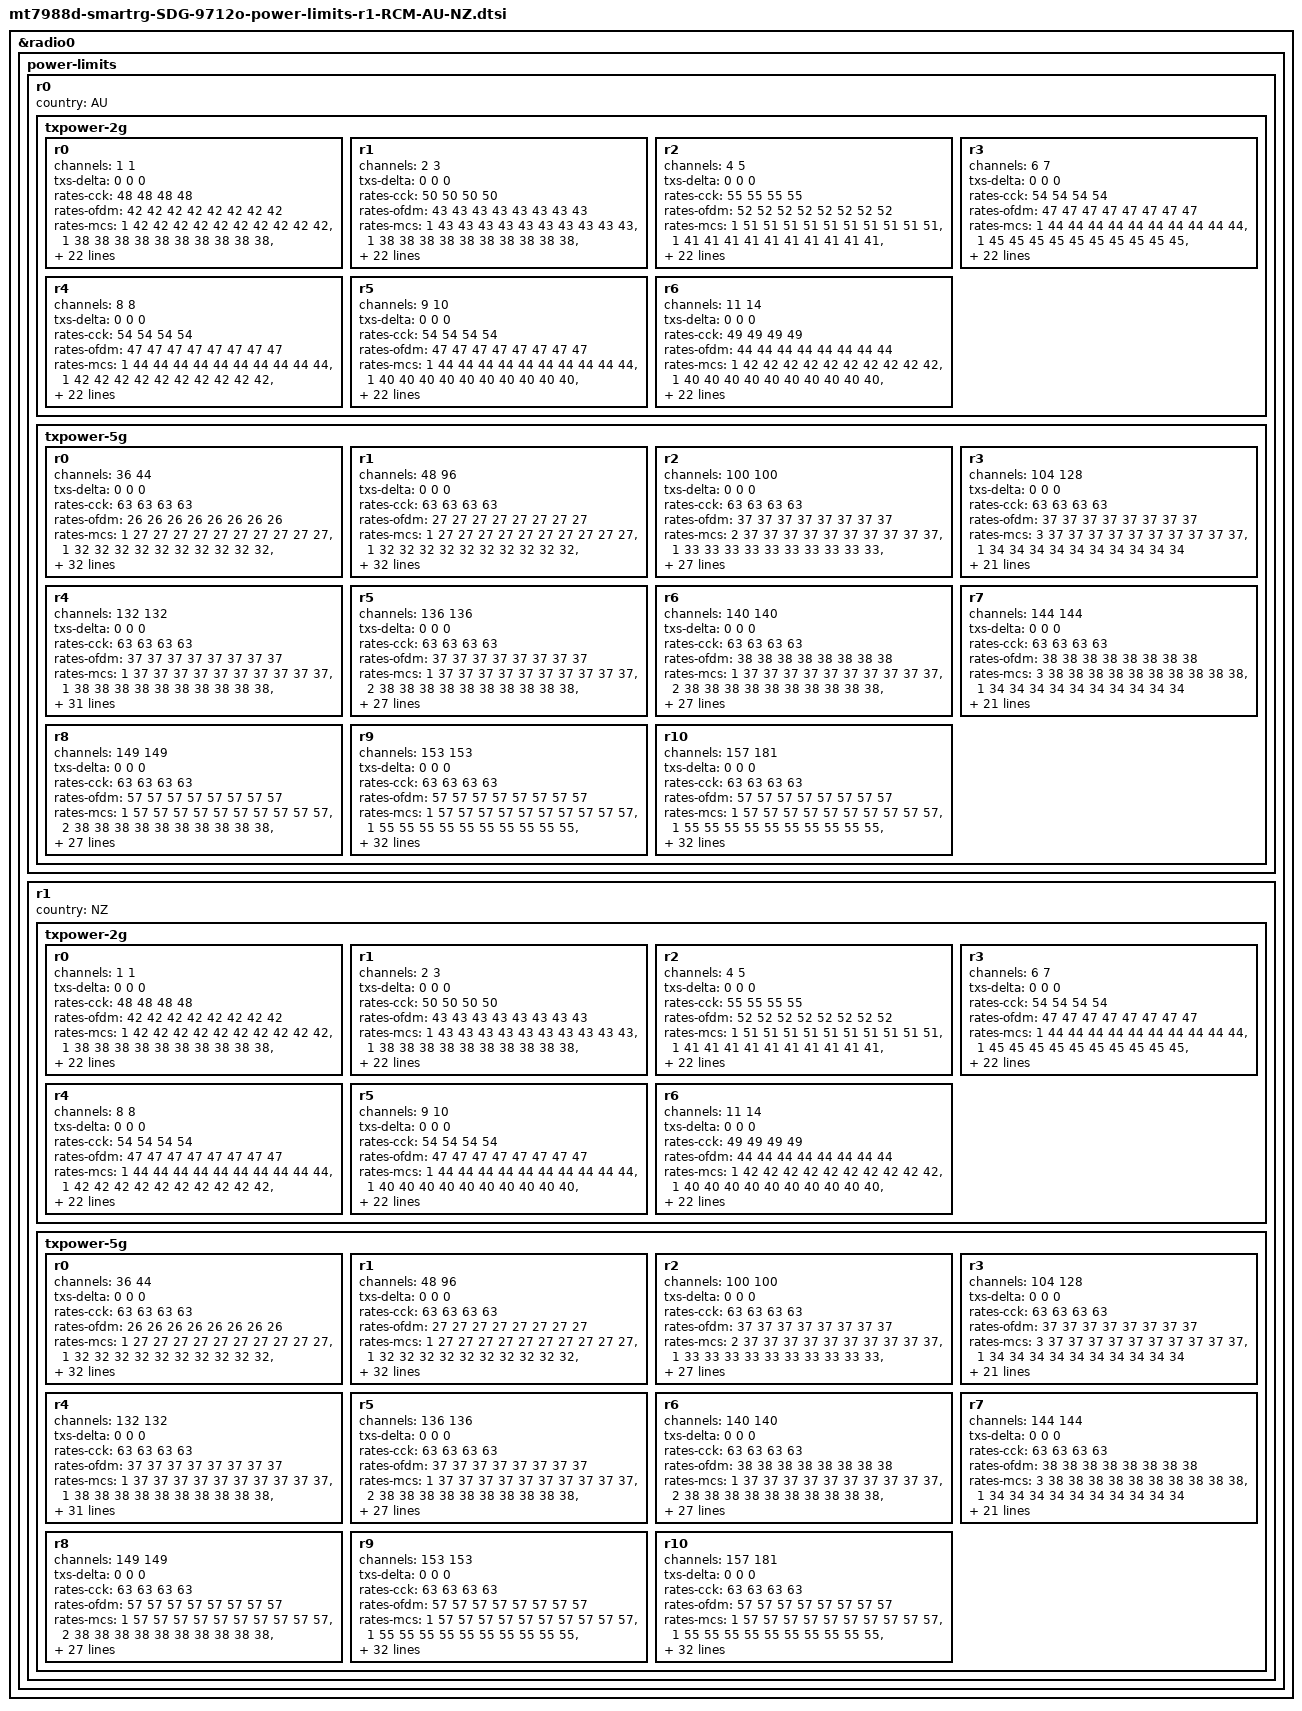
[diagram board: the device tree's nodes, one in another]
// SPDX-License-Identifier: (GPL-2.0 OR MIT)
/*
 * Copyright (C) 2024 SmartRG Inc.
 * Author: Chad Monroe <chad.monroe@smartrg.com>
 */

&radio0 {
	power-limits {
		r0 {
			country = "AU";

			txpower-2g {
				r0 {
					channels = <1 1>;
					txs-delta = <0 0 0>;
					rates-cck = /bits/ 8 <48 48 48 48>;
					rates-ofdm = /bits/ 8 <42 42 42 42 42 42 42 42>;
					rates-mcs =
					/bits/ 8 <1 42 42 42 42 42 42 42 42 42 42>,
					/bits/ 8 <1 38 38 38 38 38 38 38 38 38 38>,
					/bits/ 8 <2 63 63 63 63 63 63 63 63 63 63>;
					rates-ru =
					/bits/ 8 <4 42 42 42 42 42 42 42 42 42 42 42 42>,
					/bits/ 8 <1 38 38 38 38 38 38 38 38 38 38 38 38>,
					/bits/ 8 <2 63 63 63 63 63 63 63 63 63 63 63 63>;
					rates-eht =
					/bits/ 8 <4 42 42 42 42 42 42 42 42 42 42 42 42 42 42 42 42>,
					/bits/ 8 <1 38 38 38 38 38 38 38 38 38 38 38 38 38 38 38 38>,
					/bits/ 8 <3 63 63 63 63 63 63 63 63 63 63 63 63 63 63 63 63>,
					/bits/ 8 <2 42 42 42 42 42 42 42 42 42 42 42 42 42 42 42 42>,
					/bits/ 8 <6 63 63 63 63 63 63 63 63 63 63 63 63 63 63 63 63>;
					paths-cck = /bits/ 8 <48 42 38 36 34>;
					paths-ofdm = /bits/ 8 <42 36 32 30 28>;
					paths-ofdm-bf = /bits/ 8 <30 23 18 14>;
					paths-ru =
					/bits/ 8 <6 42 36 32 30 28 36 32 30 28 32 30 28 30 28 28>,
					/bits/ 8 <1 38 32 28 26 24 32 28 26 24 28 26 24 26 24 24>,
					/bits/ 8 <9 63 63 63 63 63 63 63 63 63 63 63 63 63 63 63>;
					paths-ru-bf =
					/bits/ 8 <6 42 30 23 18 14 36 29 24 20 32 27 24 30 26 28>,
					/bits/ 8 <1 38 26 19 14 10 32 25 20 16 28 23 20 26 22 24>,
					/bits/ 8 <9 63 63 63 63 63 63 63 63 63 63 63 63 63 63 63>;
				};
				r1 {
					channels = <2 3>;
					txs-delta = <0 0 0>;
					rates-cck = /bits/ 8 <50 50 50 50>;
					rates-ofdm = /bits/ 8 <43 43 43 43 43 43 43 43>;
					rates-mcs =
					/bits/ 8 <1 43 43 43 43 43 43 43 43 43 43>,
					/bits/ 8 <1 38 38 38 38 38 38 38 38 38 38>,
					/bits/ 8 <2 63 63 63 63 63 63 63 63 63 63>;
					rates-ru =
					/bits/ 8 <4 43 43 43 43 43 43 43 43 43 43 43 43>,
					/bits/ 8 <1 38 38 38 38 38 38 38 38 38 38 38 38>,
					/bits/ 8 <2 63 63 63 63 63 63 63 63 63 63 63 63>;
					rates-eht =
					/bits/ 8 <4 43 43 43 43 43 43 43 43 43 43 43 43 43 43 43 43>,
					/bits/ 8 <1 38 38 38 38 38 38 38 38 38 38 38 38 38 38 38 38>,
					/bits/ 8 <3 63 63 63 63 63 63 63 63 63 63 63 63 63 63 63 63>,
					/bits/ 8 <2 43 43 43 43 43 43 43 43 43 43 43 43 43 43 43 43>,
					/bits/ 8 <6 63 63 63 63 63 63 63 63 63 63 63 63 63 63 63 63>;
					paths-cck = /bits/ 8 <50 44 40 38 36>;
					paths-ofdm = /bits/ 8 <43 37 33 31 29>;
					paths-ofdm-bf = /bits/ 8 <31 24 19 15>;
					paths-ru =
					/bits/ 8 <6 43 37 33 31 29 37 33 31 29 33 31 29 31 29 29>,
					/bits/ 8 <1 38 32 28 26 24 32 28 26 24 28 26 24 26 24 24>,
					/bits/ 8 <9 63 63 63 63 63 63 63 63 63 63 63 63 63 63 63>;
					paths-ru-bf =
					/bits/ 8 <6 43 31 24 19 15 37 30 25 21 33 28 25 31 27 29>,
					/bits/ 8 <1 38 26 19 14 10 32 25 20 16 28 23 20 26 22 24>,
					/bits/ 8 <9 63 63 63 63 63 63 63 63 63 63 63 63 63 63 63>;
				};
				r2 {
					channels = <4 5>;
					txs-delta = <0 0 0>;
					rates-cck = /bits/ 8 <55 55 55 55>;
					rates-ofdm = /bits/ 8 <52 52 52 52 52 52 52 52>;
					rates-mcs =
					/bits/ 8 <1 51 51 51 51 51 51 51 51 51 51>,
					/bits/ 8 <1 41 41 41 41 41 41 41 41 41 41>,
					/bits/ 8 <2 63 63 63 63 63 63 63 63 63 63>;
					rates-ru =
					/bits/ 8 <4 51 51 51 51 51 51 51 51 51 51 51 51>,
					/bits/ 8 <1 41 41 41 41 41 41 41 41 41 41 41 41>,
					/bits/ 8 <2 63 63 63 63 63 63 63 63 63 63 63 63>;
					rates-eht =
					/bits/ 8 <4 51 51 51 51 51 51 51 51 51 51 51 51 51 51 51 51>,
					/bits/ 8 <1 41 41 41 41 41 41 41 41 41 41 41 41 41 41 41 41>,
					/bits/ 8 <3 63 63 63 63 63 63 63 63 63 63 63 63 63 63 63 63>,
					/bits/ 8 <2 51 51 51 51 51 51 51 51 51 51 51 51 51 51 51 51>,
					/bits/ 8 <6 63 63 63 63 63 63 63 63 63 63 63 63 63 63 63 63>;
					paths-cck = /bits/ 8 <55 49 45 43 41>;
					paths-ofdm = /bits/ 8 <52 46 42 40 38>;
					paths-ofdm-bf = /bits/ 8 <40 33 28 24>;
					paths-ru =
					/bits/ 8 <6 51 45 41 39 37 45 41 39 37 41 39 37 39 37 37>,
					/bits/ 8 <1 41 35 31 29 27 35 31 29 27 31 29 27 29 27 27>,
					/bits/ 8 <9 63 63 63 63 63 63 63 63 63 63 63 63 63 63 63>;
					paths-ru-bf =
					/bits/ 8 <6 51 39 32 27 23 45 38 33 29 41 36 33 39 35 37>,
					/bits/ 8 <1 41 29 22 17 13 35 28 23 19 31 26 23 29 25 27>,
					/bits/ 8 <9 63 63 63 63 63 63 63 63 63 63 63 63 63 63 63>;
				};
				r3 {
					channels = <6 7>;
					txs-delta = <0 0 0>;
					rates-cck = /bits/ 8 <54 54 54 54>;
					rates-ofdm = /bits/ 8 <47 47 47 47 47 47 47 47>;
					rates-mcs =
					/bits/ 8 <1 44 44 44 44 44 44 44 44 44 44>,
					/bits/ 8 <1 45 45 45 45 45 45 45 45 45 45>,
					/bits/ 8 <2 63 63 63 63 63 63 63 63 63 63>;
					rates-ru =
					/bits/ 8 <4 44 44 44 44 44 44 44 44 44 44 44 44>,
					/bits/ 8 <1 45 45 45 45 45 45 45 45 45 45 45 45>,
					/bits/ 8 <2 63 63 63 63 63 63 63 63 63 63 63 63>;
					rates-eht =
					/bits/ 8 <4 44 44 44 44 44 44 44 44 44 44 44 44 44 44 44 44>,
					/bits/ 8 <1 45 45 45 45 45 45 45 45 45 45 45 45 45 45 45 45>,
					/bits/ 8 <3 63 63 63 63 63 63 63 63 63 63 63 63 63 63 63 63>,
					/bits/ 8 <2 44 44 44 44 44 44 44 44 44 44 44 44 44 44 44 44>,
					/bits/ 8 <6 63 63 63 63 63 63 63 63 63 63 63 63 63 63 63 63>;
					paths-cck = /bits/ 8 <54 48 44 42 40>;
					paths-ofdm = /bits/ 8 <47 41 37 35 33>;
					paths-ofdm-bf = /bits/ 8 <35 28 23 19>;
					paths-ru =
					/bits/ 8 <6 44 38 34 32 30 38 34 32 30 34 32 30 32 30 30>,
					/bits/ 8 <1 45 39 35 33 31 39 35 33 31 35 33 31 33 31 31>,
					/bits/ 8 <9 63 63 63 63 63 63 63 63 63 63 63 63 63 63 63>;
					paths-ru-bf =
					/bits/ 8 <6 44 32 25 20 16 38 31 26 22 34 29 26 32 28 30>,
					/bits/ 8 <1 45 33 26 21 17 39 32 27 23 35 30 27 33 29 31>,
					/bits/ 8 <9 63 63 63 63 63 63 63 63 63 63 63 63 63 63 63>;
				};
				r4 {
					channels = <8 8>;
					txs-delta = <0 0 0>;
					rates-cck = /bits/ 8 <54 54 54 54>;
					rates-ofdm = /bits/ 8 <47 47 47 47 47 47 47 47>;
					rates-mcs =
					/bits/ 8 <1 44 44 44 44 44 44 44 44 44 44>,
					/bits/ 8 <1 42 42 42 42 42 42 42 42 42 42>,
					/bits/ 8 <2 63 63 63 63 63 63 63 63 63 63>;
					rates-ru =
					/bits/ 8 <4 44 44 44 44 44 44 44 44 44 44 44 44>,
					/bits/ 8 <1 42 42 42 42 42 42 42 42 42 42 42 42>,
					/bits/ 8 <2 63 63 63 63 63 63 63 63 63 63 63 63>;
					rates-eht =
					/bits/ 8 <4 44 44 44 44 44 44 44 44 44 44 44 44 44 44 44 44>,
					/bits/ 8 <1 42 42 42 42 42 42 42 42 42 42 42 42 42 42 42 42>,
					/bits/ 8 <3 63 63 63 63 63 63 63 63 63 63 63 63 63 63 63 63>,
					/bits/ 8 <2 44 44 44 44 44 44 44 44 44 44 44 44 44 44 44 44>,
					/bits/ 8 <6 63 63 63 63 63 63 63 63 63 63 63 63 63 63 63 63>;
					paths-cck = /bits/ 8 <54 48 44 42 40>;
					paths-ofdm = /bits/ 8 <47 41 37 35 33>;
					paths-ofdm-bf = /bits/ 8 <35 28 23 19>;
					paths-ru =
					/bits/ 8 <6 44 38 34 32 30 38 34 32 30 34 32 30 32 30 30>,
					/bits/ 8 <1 42 36 32 30 28 36 32 30 28 32 30 28 30 28 28>,
					/bits/ 8 <9 63 63 63 63 63 63 63 63 63 63 63 63 63 63 63>;
					paths-ru-bf =
					/bits/ 8 <6 44 32 25 20 16 38 31 26 22 34 29 26 32 28 30>,
					/bits/ 8 <1 42 30 23 18 14 36 29 24 20 32 27 24 30 26 28>,
					/bits/ 8 <9 63 63 63 63 63 63 63 63 63 63 63 63 63 63 63>;
				};
				r5 {
					channels = <9 10>;
					txs-delta = <0 0 0>;
					rates-cck = /bits/ 8 <54 54 54 54>;
					rates-ofdm = /bits/ 8 <47 47 47 47 47 47 47 47>;
					rates-mcs =
					/bits/ 8 <1 44 44 44 44 44 44 44 44 44 44>,
					/bits/ 8 <1 40 40 40 40 40 40 40 40 40 40>,
					/bits/ 8 <2 63 63 63 63 63 63 63 63 63 63>;
					rates-ru =
					/bits/ 8 <4 44 44 44 44 44 44 44 44 44 44 44 44>,
					/bits/ 8 <1 40 40 40 40 40 40 40 40 40 40 40 40>,
					/bits/ 8 <2 63 63 63 63 63 63 63 63 63 63 63 63>;
					rates-eht =
					/bits/ 8 <4 44 44 44 44 44 44 44 44 44 44 44 44 44 44 44 44>,
					/bits/ 8 <1 40 40 40 40 40 40 40 40 40 40 40 40 40 40 40 40>,
					/bits/ 8 <3 63 63 63 63 63 63 63 63 63 63 63 63 63 63 63 63>,
					/bits/ 8 <2 44 44 44 44 44 44 44 44 44 44 44 44 44 44 44 44>,
					/bits/ 8 <6 63 63 63 63 63 63 63 63 63 63 63 63 63 63 63 63>;
					paths-cck = /bits/ 8 <54 48 44 42 40>;
					paths-ofdm = /bits/ 8 <47 41 37 35 33>;
					paths-ofdm-bf = /bits/ 8 <35 28 23 19>;
					paths-ru =
					/bits/ 8 <6 44 38 34 32 30 38 34 32 30 34 32 30 32 30 30>,
					/bits/ 8 <1 40 34 30 28 26 34 30 28 26 30 28 26 28 26 26>,
					/bits/ 8 <9 63 63 63 63 63 63 63 63 63 63 63 63 63 63 63>;
					paths-ru-bf =
					/bits/ 8 <6 44 32 25 20 16 38 31 26 22 34 29 26 32 28 30>,
					/bits/ 8 <1 40 28 21 16 12 34 27 22 18 30 25 22 28 24 26>,
					/bits/ 8 <9 63 63 63 63 63 63 63 63 63 63 63 63 63 63 63>;
				};
				r6 {
					channels = <11 14>;
					txs-delta = <0 0 0>;
					rates-cck = /bits/ 8 <49 49 49 49>;
					rates-ofdm = /bits/ 8 <44 44 44 44 44 44 44 44>;
					rates-mcs =
					/bits/ 8 <1 42 42 42 42 42 42 42 42 42 42>,
					/bits/ 8 <1 40 40 40 40 40 40 40 40 40 40>,
					/bits/ 8 <2 63 63 63 63 63 63 63 63 63 63>;
					rates-ru =
					/bits/ 8 <4 42 42 42 42 42 42 42 42 42 42 42 42>,
					/bits/ 8 <1 40 40 40 40 40 40 40 40 40 40 40 40>,
					/bits/ 8 <2 63 63 63 63 63 63 63 63 63 63 63 63>;
					rates-eht =
					/bits/ 8 <4 42 42 42 42 42 42 42 42 42 42 42 42 42 42 42 42>,
					/bits/ 8 <1 40 40 40 40 40 40 40 40 40 40 40 40 40 40 40 40>,
					/bits/ 8 <3 63 63 63 63 63 63 63 63 63 63 63 63 63 63 63 63>,
					/bits/ 8 <2 42 42 42 42 42 42 42 42 42 42 42 42 42 42 42 42>,
					/bits/ 8 <6 63 63 63 63 63 63 63 63 63 63 63 63 63 63 63 63>;
					paths-cck = /bits/ 8 <49 43 39 37 35>;
					paths-ofdm = /bits/ 8 <44 38 34 32 30>;
					paths-ofdm-bf = /bits/ 8 <32 25 20 16>;
					paths-ru =
					/bits/ 8 <6 42 36 32 30 28 36 32 30 28 32 30 28 30 28 28>,
					/bits/ 8 <1 40 34 30 28 26 34 30 28 26 30 28 26 28 26 26>,
					/bits/ 8 <9 63 63 63 63 63 63 63 63 63 63 63 63 63 63 63>;
					paths-ru-bf =
					/bits/ 8 <6 42 30 23 18 14 36 29 24 20 32 27 24 30 26 28>,
					/bits/ 8 <1 40 28 21 16 12 34 27 22 18 30 25 22 28 24 26>,
					/bits/ 8 <9 63 63 63 63 63 63 63 63 63 63 63 63 63 63 63>;
				};
			};
			txpower-5g {
				r0 {
					channels = <36 44>;
					txs-delta = <0 0 0>;
					rates-cck = /bits/ 8 <63 63 63 63>;
					rates-ofdm = /bits/ 8 <26 26 26 26 26 26 26 26>;
					rates-mcs =
					/bits/ 8 <1 27 27 27 27 27 27 27 27 27 27>,
					/bits/ 8 <1 32 32 32 32 32 32 32 32 32 32>,
					/bits/ 8 <1 33 33 33 33 33 33 33 33 33 33>,
					/bits/ 8 <1 34 34 34 34 34 34 34 34 34 34>;
					rates-ru =
					/bits/ 8 <4 27 27 27 27 27 27 27 27 27 27 27 27>,
					/bits/ 8 <1 32 32 32 32 32 32 32 32 32 32 32 32>,
					/bits/ 8 <1 33 33 33 33 33 33 33 33 33 33 33 33>,
					/bits/ 8 <1 34 34 34 34 34 34 34 34 34 34 34 34>;
					rates-eht =
					/bits/ 8 <4 27 27 27 27 27 27 27 27 27 27 27 27 27 27 27 27>,
					/bits/ 8 <1 32 32 32 32 32 32 32 32 32 32 32 32 32 32 32 32>,
					/bits/ 8 <1 33 33 33 33 33 33 33 33 33 33 33 33 33 33 33 33>,
					/bits/ 8 <1 34 34 34 34 34 34 34 34 34 34 34 34 34 34 34 34>,
					/bits/ 8 <1 63 63 63 63 63 63 63 63 63 63 63 63 63 63 63 63>,
					/bits/ 8 <2 27 27 27 27 27 27 27 27 27 27 27 27 27 27 27 27>,
					/bits/ 8 <1 33 33 33 33 33 33 33 33 33 33 33 33 33 33 33 33>,
					/bits/ 8 <2 34 34 34 34 34 34 34 34 34 34 34 34 34 34 34 34>,
					/bits/ 8 <3 63 63 63 63 63 63 63 63 63 63 63 63 63 63 63 63>;
					paths-cck = /bits/ 8 <63 63 63 63 63>;
					paths-ofdm = /bits/ 8 <26 20 16 14 12>;
					paths-ofdm-bf = /bits/ 8 <14 7 2 0>;
					paths-ru =
					/bits/ 8 <6 27 21 17 15 13 21 17 15 13 17 15 13 15 13 13>,
					/bits/ 8 <1 32 26 22 20 18 26 22 20 18 22 20 18 20 18 18>,
					/bits/ 8 <2 33 27 23 21 19 27 23 21 19 23 21 19 21 19 19>,
					/bits/ 8 <3 34 28 24 22 20 28 24 22 20 24 22 20 22 20 20>,
					/bits/ 8 <4 63 63 63 63 63 63 63 63 63 63 63 63 63 63 63>;
					paths-ru-bf =
					/bits/ 8 <6 27 15 8 3 0 21 14 9 5 17 12 9 15 11 13>,
					/bits/ 8 <1 32 20 13 8 4 26 19 14 10 22 17 14 20 16 18>,
					/bits/ 8 <2 33 21 14 9 5 27 20 15 11 23 18 15 21 17 19>,
					/bits/ 8 <3 34 22 15 10 6 28 21 16 12 24 19 16 22 18 20>,
					/bits/ 8 <4 63 63 63 63 63 63 63 63 63 63 63 63 63 63 63>;
				};
				r1 {
					channels = <48 96>;
					txs-delta = <0 0 0>;
					rates-cck = /bits/ 8 <63 63 63 63>;
					rates-ofdm = /bits/ 8 <27 27 27 27 27 27 27 27>;
					rates-mcs =
					/bits/ 8 <1 27 27 27 27 27 27 27 27 27 27>,
					/bits/ 8 <1 32 32 32 32 32 32 32 32 32 32>,
					/bits/ 8 <1 33 33 33 33 33 33 33 33 33 33>,
					/bits/ 8 <1 34 34 34 34 34 34 34 34 34 34>;
					rates-ru =
					/bits/ 8 <4 27 27 27 27 27 27 27 27 27 27 27 27>,
					/bits/ 8 <1 32 32 32 32 32 32 32 32 32 32 32 32>,
					/bits/ 8 <1 33 33 33 33 33 33 33 33 33 33 33 33>,
					/bits/ 8 <1 34 34 34 34 34 34 34 34 34 34 34 34>;
					rates-eht =
					/bits/ 8 <4 27 27 27 27 27 27 27 27 27 27 27 27 27 27 27 27>,
					/bits/ 8 <1 32 32 32 32 32 32 32 32 32 32 32 32 32 32 32 32>,
					/bits/ 8 <1 33 33 33 33 33 33 33 33 33 33 33 33 33 33 33 33>,
					/bits/ 8 <1 34 34 34 34 34 34 34 34 34 34 34 34 34 34 34 34>,
					/bits/ 8 <1 63 63 63 63 63 63 63 63 63 63 63 63 63 63 63 63>,
					/bits/ 8 <2 27 27 27 27 27 27 27 27 27 27 27 27 27 27 27 27>,
					/bits/ 8 <1 33 33 33 33 33 33 33 33 33 33 33 33 33 33 33 33>,
					/bits/ 8 <2 34 34 34 34 34 34 34 34 34 34 34 34 34 34 34 34>,
					/bits/ 8 <3 63 63 63 63 63 63 63 63 63 63 63 63 63 63 63 63>;
					paths-cck = /bits/ 8 <63 63 63 63 63>;
					paths-ofdm = /bits/ 8 <27 21 17 15 13>;
					paths-ofdm-bf = /bits/ 8 <15 8 3 0>;
					paths-ru =
					/bits/ 8 <6 27 21 17 15 13 21 17 15 13 17 15 13 15 13 13>,
					/bits/ 8 <1 32 26 22 20 18 26 22 20 18 22 20 18 20 18 18>,
					/bits/ 8 <2 33 27 23 21 19 27 23 21 19 23 21 19 21 19 19>,
					/bits/ 8 <3 34 28 24 22 20 28 24 22 20 24 22 20 22 20 20>,
					/bits/ 8 <4 63 63 63 63 63 63 63 63 63 63 63 63 63 63 63>;
					paths-ru-bf =
					/bits/ 8 <6 27 15 8 3 0 21 14 9 5 17 12 9 15 11 13>,
					/bits/ 8 <1 32 20 13 8 4 26 19 14 10 22 17 14 20 16 18>,
					/bits/ 8 <2 33 21 14 9 5 27 20 15 11 23 18 15 21 17 19>,
					/bits/ 8 <3 34 22 15 10 6 28 21 16 12 24 19 16 22 18 20>,
					/bits/ 8 <4 63 63 63 63 63 63 63 63 63 63 63 63 63 63 63>;
				};
				r2 {
					channels = <100 100>;
					txs-delta = <0 0 0>;
					rates-cck = /bits/ 8 <63 63 63 63>;
					rates-ofdm = /bits/ 8 <37 37 37 37 37 37 37 37>;
					rates-mcs =
					/bits/ 8 <2 37 37 37 37 37 37 37 37 37 37>,
					/bits/ 8 <1 33 33 33 33 33 33 33 33 33 33>,
					/bits/ 8 <1 34 34 34 34 34 34 34 34 34 34>;
					rates-ru =
					/bits/ 8 <5 37 37 37 37 37 37 37 37 37 37 37 37>,
					/bits/ 8 <1 33 33 33 33 33 33 33 33 33 33 33 33>,
					/bits/ 8 <1 34 34 34 34 34 34 34 34 34 34 34 34>;
					rates-eht =
					/bits/ 8 <5 37 37 37 37 37 37 37 37 37 37 37 37 37 37 37 37>,
					/bits/ 8 <1 33 33 33 33 33 33 33 33 33 33 33 33 33 33 33 33>,
					/bits/ 8 <1 34 34 34 34 34 34 34 34 34 34 34 34 34 34 34 34>,
					/bits/ 8 <1 63 63 63 63 63 63 63 63 63 63 63 63 63 63 63 63>,
					/bits/ 8 <2 37 37 37 37 37 37 37 37 37 37 37 37 37 37 37 37>,
					/bits/ 8 <1 33 33 33 33 33 33 33 33 33 33 33 33 33 33 33 33>,
					/bits/ 8 <2 34 34 34 34 34 34 34 34 34 34 34 34 34 34 34 34>,
					/bits/ 8 <3 63 63 63 63 63 63 63 63 63 63 63 63 63 63 63 63>;
					paths-cck = /bits/ 8 <63 63 63 63 63>;
					paths-ofdm = /bits/ 8 <37 31 27 25 23>;
					paths-ofdm-bf = /bits/ 8 <25 18 13 9>;
					paths-ru =
					/bits/ 8 <7 37 31 27 25 23 31 27 25 23 27 25 23 25 23 23>,
					/bits/ 8 <2 33 27 23 21 19 27 23 21 19 23 21 19 21 19 19>,
					/bits/ 8 <3 34 28 24 22 20 28 24 22 20 24 22 20 22 20 20>,
					/bits/ 8 <4 63 63 63 63 63 63 63 63 63 63 63 63 63 63 63>;
					paths-ru-bf =
					/bits/ 8 <7 37 25 18 13 9 31 24 19 15 27 22 19 25 21 23>,
					/bits/ 8 <2 33 21 14 9 5 27 20 15 11 23 18 15 21 17 19>,
					/bits/ 8 <3 34 22 15 10 6 28 21 16 12 24 19 16 22 18 20>,
					/bits/ 8 <4 63 63 63 63 63 63 63 63 63 63 63 63 63 63 63>;
				};
				r3 {
					channels = <104 128>;
					txs-delta = <0 0 0>;
					rates-cck = /bits/ 8 <63 63 63 63>;
					rates-ofdm = /bits/ 8 <37 37 37 37 37 37 37 37>;
					rates-mcs =
					/bits/ 8 <3 37 37 37 37 37 37 37 37 37 37>,
					/bits/ 8 <1 34 34 34 34 34 34 34 34 34 34>;
					rates-ru =
					/bits/ 8 <6 37 37 37 37 37 37 37 37 37 37 37 37>,
					/bits/ 8 <1 34 34 34 34 34 34 34 34 34 34 34 34>;
					rates-eht =
					/bits/ 8 <6 37 37 37 37 37 37 37 37 37 37 37 37 37 37 37 37>,
					/bits/ 8 <1 34 34 34 34 34 34 34 34 34 34 34 34 34 34 34 34>,
					/bits/ 8 <1 63 63 63 63 63 63 63 63 63 63 63 63 63 63 63 63>,
					/bits/ 8 <3 37 37 37 37 37 37 37 37 37 37 37 37 37 37 37 37>,
					/bits/ 8 <2 34 34 34 34 34 34 34 34 34 34 34 34 34 34 34 34>,
					/bits/ 8 <3 63 63 63 63 63 63 63 63 63 63 63 63 63 63 63 63>;
					paths-cck = /bits/ 8 <63 63 63 63 63>;
					paths-ofdm = /bits/ 8 <37 31 27 25 23>;
					paths-ofdm-bf = /bits/ 8 <25 18 13 9>;
					paths-ru =
					/bits/ 8 <9 37 31 27 25 23 31 27 25 23 27 25 23 25 23 23>,
					/bits/ 8 <3 34 28 24 22 20 28 24 22 20 24 22 20 22 20 20>,
					/bits/ 8 <4 63 63 63 63 63 63 63 63 63 63 63 63 63 63 63>;
					paths-ru-bf =
					/bits/ 8 <9 37 25 18 13 9 31 24 19 15 27 22 19 25 21 23>,
					/bits/ 8 <3 34 22 15 10 6 28 21 16 12 24 19 16 22 18 20>,
					/bits/ 8 <4 63 63 63 63 63 63 63 63 63 63 63 63 63 63 63>;
				};
				r4 {
					channels = <132 132>;
					txs-delta = <0 0 0>;
					rates-cck = /bits/ 8 <63 63 63 63>;
					rates-ofdm = /bits/ 8 <37 37 37 37 37 37 37 37>;
					rates-mcs =
					/bits/ 8 <1 37 37 37 37 37 37 37 37 37 37>,
					/bits/ 8 <1 38 38 38 38 38 38 38 38 38 38>,
					/bits/ 8 <1 37 37 37 37 37 37 37 37 37 37>,
					/bits/ 8 <1 34 34 34 34 34 34 34 34 34 34>;
					rates-ru =
					/bits/ 8 <4 37 37 37 37 37 37 37 37 37 37 37 37>,
					/bits/ 8 <1 38 38 38 38 38 38 38 38 38 38 38 38>,
					/bits/ 8 <1 37 37 37 37 37 37 37 37 37 37 37 37>,
					/bits/ 8 <1 34 34 34 34 34 34 34 34 34 34 34 34>;
					rates-eht =
					/bits/ 8 <4 37 37 37 37 37 37 37 37 37 37 37 37 37 37 37 37>,
					/bits/ 8 <1 38 38 38 38 38 38 38 38 38 38 38 38 38 38 38 38>,
					/bits/ 8 <1 37 37 37 37 37 37 37 37 37 37 37 37 37 37 37 37>,
					/bits/ 8 <1 34 34 34 34 34 34 34 34 34 34 34 34 34 34 34 34>,
					/bits/ 8 <1 63 63 63 63 63 63 63 63 63 63 63 63 63 63 63 63>,
					/bits/ 8 <3 37 37 37 37 37 37 37 37 37 37 37 37 37 37 37 37>,
					/bits/ 8 <2 34 34 34 34 34 34 34 34 34 34 34 34 34 34 34 34>,
					/bits/ 8 <3 63 63 63 63 63 63 63 63 63 63 63 63 63 63 63 63>;
					paths-cck = /bits/ 8 <63 63 63 63 63>;
					paths-ofdm = /bits/ 8 <37 31 27 25 23>;
					paths-ofdm-bf = /bits/ 8 <25 18 13 9>;
					paths-ru =
					/bits/ 8 <6 37 31 27 25 23 31 27 25 23 27 25 23 25 23 23>,
					/bits/ 8 <1 38 32 28 26 24 32 28 26 24 28 26 24 26 24 24>,
					/bits/ 8 <2 37 31 27 25 23 31 27 25 23 27 25 23 25 23 23>,
					/bits/ 8 <3 34 28 24 22 20 28 24 22 20 24 22 20 22 20 20>,
					/bits/ 8 <4 63 63 63 63 63 63 63 63 63 63 63 63 63 63 63>;
					paths-ru-bf =
					/bits/ 8 <6 37 25 18 13 9 31 24 19 15 27 22 19 25 21 23>,
					/bits/ 8 <1 38 26 19 14 10 32 25 20 16 28 23 20 26 22 24>,
					/bits/ 8 <2 37 25 18 13 9 31 24 19 15 27 22 19 25 21 23>,
					/bits/ 8 <3 34 22 15 10 6 28 21 16 12 24 19 16 22 18 20>,
					/bits/ 8 <4 63 63 63 63 63 63 63 63 63 63 63 63 63 63 63>;
				};
				r5 {
					channels = <136 136>;
					txs-delta = <0 0 0>;
					rates-cck = /bits/ 8 <63 63 63 63>;
					rates-ofdm = /bits/ 8 <37 37 37 37 37 37 37 37>;
					rates-mcs =
					/bits/ 8 <1 37 37 37 37 37 37 37 37 37 37>,
					/bits/ 8 <2 38 38 38 38 38 38 38 38 38 38>,
					/bits/ 8 <1 34 34 34 34 34 34 34 34 34 34>;
					rates-ru =
					/bits/ 8 <4 37 37 37 37 37 37 37 37 37 37 37 37>,
					/bits/ 8 <2 38 38 38 38 38 38 38 38 38 38 38 38>,
					/bits/ 8 <1 34 34 34 34 34 34 34 34 34 34 34 34>;
					rates-eht =
					/bits/ 8 <4 37 37 37 37 37 37 37 37 37 37 37 37 37 37 37 37>,
					/bits/ 8 <2 38 38 38 38 38 38 38 38 38 38 38 38 38 38 38 38>,
					/bits/ 8 <1 34 34 34 34 34 34 34 34 34 34 34 34 34 34 34 34>,
					/bits/ 8 <1 63 63 63 63 63 63 63 63 63 63 63 63 63 63 63 63>,
					/bits/ 8 <2 37 37 37 37 37 37 37 37 37 37 37 37 37 37 37 37>,
					/bits/ 8 <1 38 38 38 38 38 38 38 38 38 38 38 38 38 38 38 38>,
					/bits/ 8 <2 34 34 34 34 34 34 34 34 34 34 34 34 34 34 34 34>,
					/bits/ 8 <3 63 63 63 63 63 63 63 63 63 63 63 63 63 63 63 63>;
					paths-cck = /bits/ 8 <63 63 63 63 63>;
					paths-ofdm = /bits/ 8 <37 31 27 25 23>;
					paths-ofdm-bf = /bits/ 8 <25 18 13 9>;
					paths-ru =
					/bits/ 8 <6 37 31 27 25 23 31 27 25 23 27 25 23 25 23 23>,
					/bits/ 8 <3 38 32 28 26 24 32 28 26 24 28 26 24 26 24 24>,
					/bits/ 8 <3 34 28 24 22 20 28 24 22 20 24 22 20 22 20 20>,
					/bits/ 8 <4 63 63 63 63 63 63 63 63 63 63 63 63 63 63 63>;
					paths-ru-bf =
					/bits/ 8 <6 37 25 18 13 9 31 24 19 15 27 22 19 25 21 23>,
					/bits/ 8 <3 38 26 19 14 10 32 25 20 16 28 23 20 26 22 24>,
					/bits/ 8 <3 34 22 15 10 6 28 21 16 12 24 19 16 22 18 20>,
					/bits/ 8 <4 63 63 63 63 63 63 63 63 63 63 63 63 63 63 63>;
				};
				r6 {
					channels = <140 140>;
					txs-delta = <0 0 0>;
					rates-cck = /bits/ 8 <63 63 63 63>;
					rates-ofdm = /bits/ 8 <38 38 38 38 38 38 38 38>;
					rates-mcs =
					/bits/ 8 <1 37 37 37 37 37 37 37 37 37 37>,
					/bits/ 8 <2 38 38 38 38 38 38 38 38 38 38>,
					/bits/ 8 <1 34 34 34 34 34 34 34 34 34 34>;
					rates-ru =
					/bits/ 8 <4 37 37 37 37 37 37 37 37 37 37 37 37>,
					/bits/ 8 <2 38 38 38 38 38 38 38 38 38 38 38 38>,
					/bits/ 8 <1 34 34 34 34 34 34 34 34 34 34 34 34>;
					rates-eht =
					/bits/ 8 <4 37 37 37 37 37 37 37 37 37 37 37 37 37 37 37 37>,
					/bits/ 8 <2 38 38 38 38 38 38 38 38 38 38 38 38 38 38 38 38>,
					/bits/ 8 <1 34 34 34 34 34 34 34 34 34 34 34 34 34 34 34 34>,
					/bits/ 8 <1 63 63 63 63 63 63 63 63 63 63 63 63 63 63 63 63>,
					/bits/ 8 <2 37 37 37 37 37 37 37 37 37 37 37 37 37 37 37 37>,
					/bits/ 8 <1 38 38 38 38 38 38 38 38 38 38 38 38 38 38 38 38>,
					/bits/ 8 <2 34 34 34 34 34 34 34 34 34 34 34 34 34 34 34 34>,
					/bits/ 8 <3 63 63 63 63 63 63 63 63 63 63 63 63 63 63 63 63>;
					paths-cck = /bits/ 8 <63 63 63 63 63>;
					paths-ofdm = /bits/ 8 <38 32 28 26 24>;
					paths-ofdm-bf = /bits/ 8 <26 19 14 10>;
					paths-ru =
					/bits/ 8 <6 37 31 27 25 23 31 27 25 23 27 25 23 25 23 23>,
					/bits/ 8 <3 38 32 28 26 24 32 28 26 24 28 26 24 26 24 24>,
					/bits/ 8 <3 34 28 24 22 20 28 24 22 20 24 22 20 22 20 20>,
					/bits/ 8 <4 63 63 63 63 63 63 63 63 63 63 63 63 63 63 63>;
					paths-ru-bf =
					/bits/ 8 <6 37 25 18 13 9 31 24 19 15 27 22 19 25 21 23>,
					/bits/ 8 <3 38 26 19 14 10 32 25 20 16 28 23 20 26 22 24>,
					/bits/ 8 <3 34 22 15 10 6 28 21 16 12 24 19 16 22 18 20>,
					/bits/ 8 <4 63 63 63 63 63 63 63 63 63 63 63 63 63 63 63>;
				};
				r7 {
					channels = <144 144>;
					txs-delta = <0 0 0>;
					rates-cck = /bits/ 8 <63 63 63 63>;
					rates-ofdm = /bits/ 8 <38 38 38 38 38 38 38 38>;
					rates-mcs =
					/bits/ 8 <3 38 38 38 38 38 38 38 38 38 38>,
					/bits/ 8 <1 34 34 34 34 34 34 34 34 34 34>;
					rates-ru =
					/bits/ 8 <6 38 38 38 38 38 38 38 38 38 38 38 38>,
					/bits/ 8 <1 34 34 34 34 34 34 34 34 34 34 34 34>;
					rates-eht =
					/bits/ 8 <6 38 38 38 38 38 38 38 38 38 38 38 38 38 38 38 38>,
					/bits/ 8 <1 34 34 34 34 34 34 34 34 34 34 34 34 34 34 34 34>,
					/bits/ 8 <1 63 63 63 63 63 63 63 63 63 63 63 63 63 63 63 63>,
					/bits/ 8 <3 38 38 38 38 38 38 38 38 38 38 38 38 38 38 38 38>,
					/bits/ 8 <2 34 34 34 34 34 34 34 34 34 34 34 34 34 34 34 34>,
					/bits/ 8 <3 63 63 63 63 63 63 63 63 63 63 63 63 63 63 63 63>;
					paths-cck = /bits/ 8 <63 63 63 63 63>;
					paths-ofdm = /bits/ 8 <38 32 28 26 24>;
					paths-ofdm-bf = /bits/ 8 <26 19 14 10>;
					paths-ru =
					/bits/ 8 <9 38 32 28 26 24 32 28 26 24 28 26 24 26 24 24>,
					/bits/ 8 <3 34 28 24 22 20 28 24 22 20 24 22 20 22 20 20>,
					/bits/ 8 <4 63 63 63 63 63 63 63 63 63 63 63 63 63 63 63>;
					paths-ru-bf =
					/bits/ 8 <9 38 26 19 14 10 32 25 20 16 28 23 20 26 22 24>,
					/bits/ 8 <3 34 22 15 10 6 28 21 16 12 24 19 16 22 18 20>,
					/bits/ 8 <4 63 63 63 63 63 63 63 63 63 63 63 63 63 63 63>;
				};
				r8 {
					channels = <149 149>;
					txs-delta = <0 0 0>;
					rates-cck = /bits/ 8 <63 63 63 63>;
					rates-ofdm = /bits/ 8 <57 57 57 57 57 57 57 57>;
					rates-mcs =
					/bits/ 8 <1 57 57 57 57 57 57 57 57 57 57>,
					/bits/ 8 <2 38 38 38 38 38 38 38 38 38 38>,
					/bits/ 8 <1 34 34 34 34 34 34 34 34 34 34>;
					rates-ru =
					/bits/ 8 <4 57 57 57 57 57 57 57 57 57 57 57 57>,
					/bits/ 8 <2 38 38 38 38 38 38 38 38 38 38 38 38>,
					/bits/ 8 <1 34 34 34 34 34 34 34 34 34 34 34 34>;
					rates-eht =
					/bits/ 8 <4 57 57 57 57 57 57 57 57 57 57 57 57 57 57 57 57>,
					/bits/ 8 <2 38 38 38 38 38 38 38 38 38 38 38 38 38 38 38 38>,
					/bits/ 8 <1 34 34 34 34 34 34 34 34 34 34 34 34 34 34 34 34>,
					/bits/ 8 <1 63 63 63 63 63 63 63 63 63 63 63 63 63 63 63 63>,
					/bits/ 8 <2 57 57 57 57 57 57 57 57 57 57 57 57 57 57 57 57>,
					/bits/ 8 <1 38 38 38 38 38 38 38 38 38 38 38 38 38 38 38 38>,
					/bits/ 8 <2 34 34 34 34 34 34 34 34 34 34 34 34 34 34 34 34>,
					/bits/ 8 <3 63 63 63 63 63 63 63 63 63 63 63 63 63 63 63 63>;
					paths-cck = /bits/ 8 <63 63 63 63 63>;
					paths-ofdm = /bits/ 8 <57 51 47 45 43>;
					paths-ofdm-bf = /bits/ 8 <45 38 33 29>;
					paths-ru =
					/bits/ 8 <6 57 51 47 45 43 51 47 45 43 47 45 43 45 43 43>,
					/bits/ 8 <3 38 32 28 26 24 32 28 26 24 28 26 24 26 24 24>,
					/bits/ 8 <3 34 28 24 22 20 28 24 22 20 24 22 20 22 20 20>,
					/bits/ 8 <4 63 63 63 63 63 63 63 63 63 63 63 63 63 63 63>;
					paths-ru-bf =
					/bits/ 8 <6 57 45 38 33 29 51 44 39 35 47 42 39 45 41 43>,
					/bits/ 8 <3 38 26 19 14 10 32 25 20 16 28 23 20 26 22 24>,
					/bits/ 8 <3 34 22 15 10 6 28 21 16 12 24 19 16 22 18 20>,
					/bits/ 8 <4 63 63 63 63 63 63 63 63 63 63 63 63 63 63 63>;
				};
				r9 {
					channels = <153 153>;
					txs-delta = <0 0 0>;
					rates-cck = /bits/ 8 <63 63 63 63>;
					rates-ofdm = /bits/ 8 <57 57 57 57 57 57 57 57>;
					rates-mcs =
					/bits/ 8 <1 57 57 57 57 57 57 57 57 57 57>,
					/bits/ 8 <1 55 55 55 55 55 55 55 55 55 55>,
					/bits/ 8 <1 38 38 38 38 38 38 38 38 38 38>,
					/bits/ 8 <1 34 34 34 34 34 34 34 34 34 34>;
					rates-ru =
					/bits/ 8 <4 57 57 57 57 57 57 57 57 57 57 57 57>,
					/bits/ 8 <1 55 55 55 55 55 55 55 55 55 55 55 55>,
					/bits/ 8 <1 38 38 38 38 38 38 38 38 38 38 38 38>,
					/bits/ 8 <1 34 34 34 34 34 34 34 34 34 34 34 34>;
					rates-eht =
					/bits/ 8 <4 57 57 57 57 57 57 57 57 57 57 57 57 57 57 57 57>,
					/bits/ 8 <1 55 55 55 55 55 55 55 55 55 55 55 55 55 55 55 55>,
					/bits/ 8 <1 38 38 38 38 38 38 38 38 38 38 38 38 38 38 38 38>,
					/bits/ 8 <1 34 34 34 34 34 34 34 34 34 34 34 34 34 34 34 34>,
					/bits/ 8 <1 63 63 63 63 63 63 63 63 63 63 63 63 63 63 63 63>,
					/bits/ 8 <2 57 57 57 57 57 57 57 57 57 57 57 57 57 57 57 57>,
					/bits/ 8 <1 38 38 38 38 38 38 38 38 38 38 38 38 38 38 38 38>,
					/bits/ 8 <2 34 34 34 34 34 34 34 34 34 34 34 34 34 34 34 34>,
					/bits/ 8 <3 63 63 63 63 63 63 63 63 63 63 63 63 63 63 63 63>;
					paths-cck = /bits/ 8 <63 63 63 63 63>;
					paths-ofdm = /bits/ 8 <57 51 47 45 43>;
					paths-ofdm-bf = /bits/ 8 <45 38 33 29>;
					paths-ru =
					/bits/ 8 <6 57 51 47 45 43 51 47 45 43 47 45 43 45 43 43>,
					/bits/ 8 <1 55 49 45 43 41 49 45 43 41 45 43 41 43 41 41>,
					/bits/ 8 <2 38 32 28 26 24 32 28 26 24 28 26 24 26 24 24>,
					/bits/ 8 <3 34 28 24 22 20 28 24 22 20 24 22 20 22 20 20>,
					/bits/ 8 <4 63 63 63 63 63 63 63 63 63 63 63 63 63 63 63>;
					paths-ru-bf =
					/bits/ 8 <6 57 45 38 33 29 51 44 39 35 47 42 39 45 41 43>,
					/bits/ 8 <1 55 43 36 31 27 49 42 37 33 45 40 37 43 39 41>,
					/bits/ 8 <2 38 26 19 14 10 32 25 20 16 28 23 20 26 22 24>,
					/bits/ 8 <3 34 22 15 10 6 28 21 16 12 24 19 16 22 18 20>,
					/bits/ 8 <4 63 63 63 63 63 63 63 63 63 63 63 63 63 63 63>;
				};
				r10 {
					channels = <157 181>;
					txs-delta = <0 0 0>;
					rates-cck = /bits/ 8 <63 63 63 63>;
					rates-ofdm = /bits/ 8 <57 57 57 57 57 57 57 57>;
					rates-mcs =
					/bits/ 8 <1 57 57 57 57 57 57 57 57 57 57>,
					/bits/ 8 <1 55 55 55 55 55 55 55 55 55 55>,
					/bits/ 8 <1 50 50 50 50 50 50 50 50 50 50>,
					/bits/ 8 <1 34 34 34 34 34 34 34 34 34 34>;
					rates-ru =
					/bits/ 8 <4 57 57 57 57 57 57 57 57 57 57 57 57>,
					/bits/ 8 <1 55 55 55 55 55 55 55 55 55 55 55 55>,
					/bits/ 8 <1 50 50 50 50 50 50 50 50 50 50 50 50>,
					/bits/ 8 <1 34 34 34 34 34 34 34 34 34 34 34 34>;
					rates-eht =
					/bits/ 8 <4 57 57 57 57 57 57 57 57 57 57 57 57 57 57 57 57>,
					/bits/ 8 <1 55 55 55 55 55 55 55 55 55 55 55 55 55 55 55 55>,
					/bits/ 8 <1 50 50 50 50 50 50 50 50 50 50 50 50 50 50 50 50>,
					/bits/ 8 <1 34 34 34 34 34 34 34 34 34 34 34 34 34 34 34 34>,
					/bits/ 8 <1 63 63 63 63 63 63 63 63 63 63 63 63 63 63 63 63>,
					/bits/ 8 <2 57 57 57 57 57 57 57 57 57 57 57 57 57 57 57 57>,
					/bits/ 8 <1 50 50 50 50 50 50 50 50 50 50 50 50 50 50 50 50>,
					/bits/ 8 <2 34 34 34 34 34 34 34 34 34 34 34 34 34 34 34 34>,
					/bits/ 8 <3 63 63 63 63 63 63 63 63 63 63 63 63 63 63 63 63>;
					paths-cck = /bits/ 8 <63 63 63 63 63>;
					paths-ofdm = /bits/ 8 <57 51 47 45 43>;
					paths-ofdm-bf = /bits/ 8 <45 38 33 29>;
					paths-ru =
					/bits/ 8 <6 57 51 47 45 43 51 47 45 43 47 45 43 45 43 43>,
					/bits/ 8 <1 55 49 45 43 41 49 45 43 41 45 43 41 43 41 41>,
					/bits/ 8 <2 50 44 40 38 36 44 40 38 36 40 38 36 38 36 36>,
					/bits/ 8 <3 34 28 24 22 20 28 24 22 20 24 22 20 22 20 20>,
					/bits/ 8 <4 63 63 63 63 63 63 63 63 63 63 63 63 63 63 63>;
					paths-ru-bf =
					/bits/ 8 <6 57 45 38 33 29 51 44 39 35 47 42 39 45 41 43>,
					/bits/ 8 <1 55 43 36 31 27 49 42 37 33 45 40 37 43 39 41>,
					/bits/ 8 <2 50 38 31 26 22 44 37 32 28 40 35 32 38 34 36>,
					/bits/ 8 <3 34 22 15 10 6 28 21 16 12 24 19 16 22 18 20>,
					/bits/ 8 <4 63 63 63 63 63 63 63 63 63 63 63 63 63 63 63>;
				};
			};
		};

		r1 {
			country = "NZ";

			txpower-2g {
				r0 {
					channels = <1 1>;
					txs-delta = <0 0 0>;
					rates-cck = /bits/ 8 <48 48 48 48>;
					rates-ofdm = /bits/ 8 <42 42 42 42 42 42 42 42>;
					rates-mcs =
					/bits/ 8 <1 42 42 42 42 42 42 42 42 42 42>,
					/bits/ 8 <1 38 38 38 38 38 38 38 38 38 38>,
					/bits/ 8 <2 63 63 63 63 63 63 63 63 63 63>;
					rates-ru =
					/bits/ 8 <4 42 42 42 42 42 42 42 42 42 42 42 42>,
					/bits/ 8 <1 38 38 38 38 38 38 38 38 38 38 38 38>,
					/bits/ 8 <2 63 63 63 63 63 63 63 63 63 63 63 63>;
					rates-eht =
					/bits/ 8 <4 42 42 42 42 42 42 42 42 42 42 42 42 42 42 42 42>,
					/bits/ 8 <1 38 38 38 38 38 38 38 38 38 38 38 38 38 38 38 38>,
					/bits/ 8 <3 63 63 63 63 63 63 63 63 63 63 63 63 63 63 63 63>,
					/bits/ 8 <2 42 42 42 42 42 42 42 42 42 42 42 42 42 42 42 42>,
					/bits/ 8 <6 63 63 63 63 63 63 63 63 63 63 63 63 63 63 63 63>;
					paths-cck = /bits/ 8 <48 42 38 36 34>;
					paths-ofdm = /bits/ 8 <42 36 32 30 28>;
					paths-ofdm-bf = /bits/ 8 <30 23 18 14>;
					paths-ru =
					/bits/ 8 <6 42 36 32 30 28 36 32 30 28 32 30 28 30 28 28>,
					/bits/ 8 <1 38 32 28 26 24 32 28 26 24 28 26 24 26 24 24>,
					/bits/ 8 <9 63 63 63 63 63 63 63 63 63 63 63 63 63 63 63>;
					paths-ru-bf =
					/bits/ 8 <6 42 30 23 18 14 36 29 24 20 32 27 24 30 26 28>,
					/bits/ 8 <1 38 26 19 14 10 32 25 20 16 28 23 20 26 22 24>,
					/bits/ 8 <9 63 63 63 63 63 63 63 63 63 63 63 63 63 63 63>;
				};
				r1 {
					channels = <2 3>;
					txs-delta = <0 0 0>;
					rates-cck = /bits/ 8 <50 50 50 50>;
					rates-ofdm = /bits/ 8 <43 43 43 43 43 43 43 43>;
					rates-mcs =
					/bits/ 8 <1 43 43 43 43 43 43 43 43 43 43>,
					/bits/ 8 <1 38 38 38 38 38 38 38 38 38 38>,
					/bits/ 8 <2 63 63 63 63 63 63 63 63 63 63>;
					rates-ru =
					/bits/ 8 <4 43 43 43 43 43 43 43 43 43 43 43 43>,
					/bits/ 8 <1 38 38 38 38 38 38 38 38 38 38 38 38>,
					/bits/ 8 <2 63 63 63 63 63 63 63 63 63 63 63 63>;
					rates-eht =
					/bits/ 8 <4 43 43 43 43 43 43 43 43 43 43 43 43 43 43 43 43>,
					/bits/ 8 <1 38 38 38 38 38 38 38 38 38 38 38 38 38 38 38 38>,
					/bits/ 8 <3 63 63 63 63 63 63 63 63 63 63 63 63 63 63 63 63>,
					/bits/ 8 <2 43 43 43 43 43 43 43 43 43 43 43 43 43 43 43 43>,
					/bits/ 8 <6 63 63 63 63 63 63 63 63 63 63 63 63 63 63 63 63>;
					paths-cck = /bits/ 8 <50 44 40 38 36>;
					paths-ofdm = /bits/ 8 <43 37 33 31 29>;
					paths-ofdm-bf = /bits/ 8 <31 24 19 15>;
					paths-ru =
					/bits/ 8 <6 43 37 33 31 29 37 33 31 29 33 31 29 31 29 29>,
					/bits/ 8 <1 38 32 28 26 24 32 28 26 24 28 26 24 26 24 24>,
					/bits/ 8 <9 63 63 63 63 63 63 63 63 63 63 63 63 63 63 63>;
					paths-ru-bf =
					/bits/ 8 <6 43 31 24 19 15 37 30 25 21 33 28 25 31 27 29>,
					/bits/ 8 <1 38 26 19 14 10 32 25 20 16 28 23 20 26 22 24>,
					/bits/ 8 <9 63 63 63 63 63 63 63 63 63 63 63 63 63 63 63>;
				};
				r2 {
					channels = <4 5>;
					txs-delta = <0 0 0>;
					rates-cck = /bits/ 8 <55 55 55 55>;
					rates-ofdm = /bits/ 8 <52 52 52 52 52 52 52 52>;
					rates-mcs =
					/bits/ 8 <1 51 51 51 51 51 51 51 51 51 51>,
					/bits/ 8 <1 41 41 41 41 41 41 41 41 41 41>,
					/bits/ 8 <2 63 63 63 63 63 63 63 63 63 63>;
					rates-ru =
					/bits/ 8 <4 51 51 51 51 51 51 51 51 51 51 51 51>,
					/bits/ 8 <1 41 41 41 41 41 41 41 41 41 41 41 41>,
					/bits/ 8 <2 63 63 63 63 63 63 63 63 63 63 63 63>;
					rates-eht =
					/bits/ 8 <4 51 51 51 51 51 51 51 51 51 51 51 51 51 51 51 51>,
					/bits/ 8 <1 41 41 41 41 41 41 41 41 41 41 41 41 41 41 41 41>,
					/bits/ 8 <3 63 63 63 63 63 63 63 63 63 63 63 63 63 63 63 63>,
					/bits/ 8 <2 51 51 51 51 51 51 51 51 51 51 51 51 51 51 51 51>,
					/bits/ 8 <6 63 63 63 63 63 63 63 63 63 63 63 63 63 63 63 63>;
					paths-cck = /bits/ 8 <55 49 45 43 41>;
					paths-ofdm = /bits/ 8 <52 46 42 40 38>;
					paths-ofdm-bf = /bits/ 8 <40 33 28 24>;
					paths-ru =
					/bits/ 8 <6 51 45 41 39 37 45 41 39 37 41 39 37 39 37 37>,
					/bits/ 8 <1 41 35 31 29 27 35 31 29 27 31 29 27 29 27 27>,
					/bits/ 8 <9 63 63 63 63 63 63 63 63 63 63 63 63 63 63 63>;
					paths-ru-bf =
					/bits/ 8 <6 51 39 32 27 23 45 38 33 29 41 36 33 39 35 37>,
					/bits/ 8 <1 41 29 22 17 13 35 28 23 19 31 26 23 29 25 27>,
					/bits/ 8 <9 63 63 63 63 63 63 63 63 63 63 63 63 63 63 63>;
				};
				r3 {
					channels = <6 7>;
					txs-delta = <0 0 0>;
					rates-cck = /bits/ 8 <54 54 54 54>;
					rates-ofdm = /bits/ 8 <47 47 47 47 47 47 47 47>;
					rates-mcs =
					/bits/ 8 <1 44 44 44 44 44 44 44 44 44 44>,
					/bits/ 8 <1 45 45 45 45 45 45 45 45 45 45>,
					/bits/ 8 <2 63 63 63 63 63 63 63 63 63 63>;
					rates-ru =
					/bits/ 8 <4 44 44 44 44 44 44 44 44 44 44 44 44>,
					/bits/ 8 <1 45 45 45 45 45 45 45 45 45 45 45 45>,
					/bits/ 8 <2 63 63 63 63 63 63 63 63 63 63 63 63>;
					rates-eht =
					/bits/ 8 <4 44 44 44 44 44 44 44 44 44 44 44 44 44 44 44 44>,
					/bits/ 8 <1 45 45 45 45 45 45 45 45 45 45 45 45 45 45 45 45>,
					/bits/ 8 <3 63 63 63 63 63 63 63 63 63 63 63 63 63 63 63 63>,
					/bits/ 8 <2 44 44 44 44 44 44 44 44 44 44 44 44 44 44 44 44>,
					/bits/ 8 <6 63 63 63 63 63 63 63 63 63 63 63 63 63 63 63 63>;
					paths-cck = /bits/ 8 <54 48 44 42 40>;
					paths-ofdm = /bits/ 8 <47 41 37 35 33>;
					paths-ofdm-bf = /bits/ 8 <35 28 23 19>;
					paths-ru =
					/bits/ 8 <6 44 38 34 32 30 38 34 32 30 34 32 30 32 30 30>,
					/bits/ 8 <1 45 39 35 33 31 39 35 33 31 35 33 31 33 31 31>,
					/bits/ 8 <9 63 63 63 63 63 63 63 63 63 63 63 63 63 63 63>;
					paths-ru-bf =
					/bits/ 8 <6 44 32 25 20 16 38 31 26 22 34 29 26 32 28 30>,
					/bits/ 8 <1 45 33 26 21 17 39 32 27 23 35 30 27 33 29 31>,
					/bits/ 8 <9 63 63 63 63 63 63 63 63 63 63 63 63 63 63 63>;
				};
				r4 {
					channels = <8 8>;
					txs-delta = <0 0 0>;
					rates-cck = /bits/ 8 <54 54 54 54>;
					rates-ofdm = /bits/ 8 <47 47 47 47 47 47 47 47>;
					rates-mcs =
					/bits/ 8 <1 44 44 44 44 44 44 44 44 44 44>,
					/bits/ 8 <1 42 42 42 42 42 42 42 42 42 42>,
					/bits/ 8 <2 63 63 63 63 63 63 63 63 63 63>;
					rates-ru =
					/bits/ 8 <4 44 44 44 44 44 44 44 44 44 44 44 44>,
					/bits/ 8 <1 42 42 42 42 42 42 42 42 42 42 42 42>,
					/bits/ 8 <2 63 63 63 63 63 63 63 63 63 63 63 63>;
					rates-eht =
					/bits/ 8 <4 44 44 44 44 44 44 44 44 44 44 44 44 44 44 44 44>,
					/bits/ 8 <1 42 42 42 42 42 42 42 42 42 42 42 42 42 42 42 42>,
					/bits/ 8 <3 63 63 63 63 63 63 63 63 63 63 63 63 63 63 63 63>,
					/bits/ 8 <2 44 44 44 44 44 44 44 44 44 44 44 44 44 44 44 44>,
					/bits/ 8 <6 63 63 63 63 63 63 63 63 63 63 63 63 63 63 63 63>;
					paths-cck = /bits/ 8 <54 48 44 42 40>;
					paths-ofdm = /bits/ 8 <47 41 37 35 33>;
					paths-ofdm-bf = /bits/ 8 <35 28 23 19>;
					paths-ru =
					/bits/ 8 <6 44 38 34 32 30 38 34 32 30 34 32 30 32 30 30>,
					/bits/ 8 <1 42 36 32 30 28 36 32 30 28 32 30 28 30 28 28>,
					/bits/ 8 <9 63 63 63 63 63 63 63 63 63 63 63 63 63 63 63>;
					paths-ru-bf =
					/bits/ 8 <6 44 32 25 20 16 38 31 26 22 34 29 26 32 28 30>,
					/bits/ 8 <1 42 30 23 18 14 36 29 24 20 32 27 24 30 26 28>,
					/bits/ 8 <9 63 63 63 63 63 63 63 63 63 63 63 63 63 63 63>;
				};
				r5 {
					channels = <9 10>;
					txs-delta = <0 0 0>;
					rates-cck = /bits/ 8 <54 54 54 54>;
					rates-ofdm = /bits/ 8 <47 47 47 47 47 47 47 47>;
					rates-mcs =
					/bits/ 8 <1 44 44 44 44 44 44 44 44 44 44>,
					/bits/ 8 <1 40 40 40 40 40 40 40 40 40 40>,
					/bits/ 8 <2 63 63 63 63 63 63 63 63 63 63>;
					rates-ru =
					/bits/ 8 <4 44 44 44 44 44 44 44 44 44 44 44 44>,
					/bits/ 8 <1 40 40 40 40 40 40 40 40 40 40 40 40>,
					/bits/ 8 <2 63 63 63 63 63 63 63 63 63 63 63 63>;
					rates-eht =
					/bits/ 8 <4 44 44 44 44 44 44 44 44 44 44 44 44 44 44 44 44>,
					/bits/ 8 <1 40 40 40 40 40 40 40 40 40 40 40 40 40 40 40 40>,
					/bits/ 8 <3 63 63 63 63 63 63 63 63 63 63 63 63 63 63 63 63>,
					/bits/ 8 <2 44 44 44 44 44 44 44 44 44 44 44 44 44 44 44 44>,
					/bits/ 8 <6 63 63 63 63 63 63 63 63 63 63 63 63 63 63 63 63>;
					paths-cck = /bits/ 8 <54 48 44 42 40>;
					paths-ofdm = /bits/ 8 <47 41 37 35 33>;
					paths-ofdm-bf = /bits/ 8 <35 28 23 19>;
					paths-ru =
					/bits/ 8 <6 44 38 34 32 30 38 34 32 30 34 32 30 32 30 30>,
					/bits/ 8 <1 40 34 30 28 26 34 30 28 26 30 28 26 28 26 26>,
					/bits/ 8 <9 63 63 63 63 63 63 63 63 63 63 63 63 63 63 63>;
					paths-ru-bf =
					/bits/ 8 <6 44 32 25 20 16 38 31 26 22 34 29 26 32 28 30>,
					/bits/ 8 <1 40 28 21 16 12 34 27 22 18 30 25 22 28 24 26>,
					/bits/ 8 <9 63 63 63 63 63 63 63 63 63 63 63 63 63 63 63>;
				};
				r6 {
					channels = <11 14>;
					txs-delta = <0 0 0>;
					rates-cck = /bits/ 8 <49 49 49 49>;
					rates-ofdm = /bits/ 8 <44 44 44 44 44 44 44 44>;
					rates-mcs =
					/bits/ 8 <1 42 42 42 42 42 42 42 42 42 42>,
					/bits/ 8 <1 40 40 40 40 40 40 40 40 40 40>,
					/bits/ 8 <2 63 63 63 63 63 63 63 63 63 63>;
					rates-ru =
					/bits/ 8 <4 42 42 42 42 42 42 42 42 42 42 42 42>,
					/bits/ 8 <1 40 40 40 40 40 40 40 40 40 40 40 40>,
					/bits/ 8 <2 63 63 63 63 63 63 63 63 63 63 63 63>;
					rates-eht =
					/bits/ 8 <4 42 42 42 42 42 42 42 42 42 42 42 42 42 42 42 42>,
					/bits/ 8 <1 40 40 40 40 40 40 40 40 40 40 40 40 40 40 40 40>,
					/bits/ 8 <3 63 63 63 63 63 63 63 63 63 63 63 63 63 63 63 63>,
					/bits/ 8 <2 42 42 42 42 42 42 42 42 42 42 42 42 42 42 42 42>,
					/bits/ 8 <6 63 63 63 63 63 63 63 63 63 63 63 63 63 63 63 63>;
					paths-cck = /bits/ 8 <49 43 39 37 35>;
					paths-ofdm = /bits/ 8 <44 38 34 32 30>;
					paths-ofdm-bf = /bits/ 8 <32 25 20 16>;
					paths-ru =
					/bits/ 8 <6 42 36 32 30 28 36 32 30 28 32 30 28 30 28 28>,
					/bits/ 8 <1 40 34 30 28 26 34 30 28 26 30 28 26 28 26 26>,
					/bits/ 8 <9 63 63 63 63 63 63 63 63 63 63 63 63 63 63 63>;
					paths-ru-bf =
					/bits/ 8 <6 42 30 23 18 14 36 29 24 20 32 27 24 30 26 28>,
					/bits/ 8 <1 40 28 21 16 12 34 27 22 18 30 25 22 28 24 26>,
					/bits/ 8 <9 63 63 63 63 63 63 63 63 63 63 63 63 63 63 63>;
				};
			};
			txpower-5g {
				r0 {
					channels = <36 44>;
					txs-delta = <0 0 0>;
					rates-cck = /bits/ 8 <63 63 63 63>;
					rates-ofdm = /bits/ 8 <26 26 26 26 26 26 26 26>;
					rates-mcs =
					/bits/ 8 <1 27 27 27 27 27 27 27 27 27 27>,
					/bits/ 8 <1 32 32 32 32 32 32 32 32 32 32>,
					/bits/ 8 <1 33 33 33 33 33 33 33 33 33 33>,
					/bits/ 8 <1 34 34 34 34 34 34 34 34 34 34>;
					rates-ru =
					/bits/ 8 <4 27 27 27 27 27 27 27 27 27 27 27 27>,
					/bits/ 8 <1 32 32 32 32 32 32 32 32 32 32 32 32>,
					/bits/ 8 <1 33 33 33 33 33 33 33 33 33 33 33 33>,
					/bits/ 8 <1 34 34 34 34 34 34 34 34 34 34 34 34>;
					rates-eht =
					/bits/ 8 <4 27 27 27 27 27 27 27 27 27 27 27 27 27 27 27 27>,
					/bits/ 8 <1 32 32 32 32 32 32 32 32 32 32 32 32 32 32 32 32>,
					/bits/ 8 <1 33 33 33 33 33 33 33 33 33 33 33 33 33 33 33 33>,
					/bits/ 8 <1 34 34 34 34 34 34 34 34 34 34 34 34 34 34 34 34>,
					/bits/ 8 <1 63 63 63 63 63 63 63 63 63 63 63 63 63 63 63 63>,
					/bits/ 8 <2 27 27 27 27 27 27 27 27 27 27 27 27 27 27 27 27>,
					/bits/ 8 <1 33 33 33 33 33 33 33 33 33 33 33 33 33 33 33 33>,
					/bits/ 8 <2 34 34 34 34 34 34 34 34 34 34 34 34 34 34 34 34>,
					/bits/ 8 <3 63 63 63 63 63 63 63 63 63 63 63 63 63 63 63 63>;
					paths-cck = /bits/ 8 <63 63 63 63 63>;
					paths-ofdm = /bits/ 8 <26 20 16 14 12>;
					paths-ofdm-bf = /bits/ 8 <14 7 2 0>;
					paths-ru =
					/bits/ 8 <6 27 21 17 15 13 21 17 15 13 17 15 13 15 13 13>,
					/bits/ 8 <1 32 26 22 20 18 26 22 20 18 22 20 18 20 18 18>,
					/bits/ 8 <2 33 27 23 21 19 27 23 21 19 23 21 19 21 19 19>,
					/bits/ 8 <3 34 28 24 22 20 28 24 22 20 24 22 20 22 20 20>,
					/bits/ 8 <4 63 63 63 63 63 63 63 63 63 63 63 63 63 63 63>;
					paths-ru-bf =
					/bits/ 8 <6 27 15 8 3 0 21 14 9 5 17 12 9 15 11 13>,
					/bits/ 8 <1 32 20 13 8 4 26 19 14 10 22 17 14 20 16 18>,
					/bits/ 8 <2 33 21 14 9 5 27 20 15 11 23 18 15 21 17 19>,
					/bits/ 8 <3 34 22 15 10 6 28 21 16 12 24 19 16 22 18 20>,
					/bits/ 8 <4 63 63 63 63 63 63 63 63 63 63 63 63 63 63 63>;
				};
				r1 {
					channels = <48 96>;
					txs-delta = <0 0 0>;
					rates-cck = /bits/ 8 <63 63 63 63>;
					rates-ofdm = /bits/ 8 <27 27 27 27 27 27 27 27>;
					rates-mcs =
					/bits/ 8 <1 27 27 27 27 27 27 27 27 27 27>,
					/bits/ 8 <1 32 32 32 32 32 32 32 32 32 32>,
					/bits/ 8 <1 33 33 33 33 33 33 33 33 33 33>,
					/bits/ 8 <1 34 34 34 34 34 34 34 34 34 34>;
					rates-ru =
					/bits/ 8 <4 27 27 27 27 27 27 27 27 27 27 27 27>,
					/bits/ 8 <1 32 32 32 32 32 32 32 32 32 32 32 32>,
					/bits/ 8 <1 33 33 33 33 33 33 33 33 33 33 33 33>,
					/bits/ 8 <1 34 34 34 34 34 34 34 34 34 34 34 34>;
					rates-eht =
					/bits/ 8 <4 27 27 27 27 27 27 27 27 27 27 27 27 27 27 27 27>,
					/bits/ 8 <1 32 32 32 32 32 32 32 32 32 32 32 32 32 32 32 32>,
					/bits/ 8 <1 33 33 33 33 33 33 33 33 33 33 33 33 33 33 33 33>,
					/bits/ 8 <1 34 34 34 34 34 34 34 34 34 34 34 34 34 34 34 34>,
					/bits/ 8 <1 63 63 63 63 63 63 63 63 63 63 63 63 63 63 63 63>,
					/bits/ 8 <2 27 27 27 27 27 27 27 27 27 27 27 27 27 27 27 27>,
					/bits/ 8 <1 33 33 33 33 33 33 33 33 33 33 33 33 33 33 33 33>,
					/bits/ 8 <2 34 34 34 34 34 34 34 34 34 34 34 34 34 34 34 34>,
					/bits/ 8 <3 63 63 63 63 63 63 63 63 63 63 63 63 63 63 63 63>;
					paths-cck = /bits/ 8 <63 63 63 63 63>;
					paths-ofdm = /bits/ 8 <27 21 17 15 13>;
					paths-ofdm-bf = /bits/ 8 <15 8 3 0>;
					paths-ru =
					/bits/ 8 <6 27 21 17 15 13 21 17 15 13 17 15 13 15 13 13>,
					/bits/ 8 <1 32 26 22 20 18 26 22 20 18 22 20 18 20 18 18>,
					/bits/ 8 <2 33 27 23 21 19 27 23 21 19 23 21 19 21 19 19>,
					/bits/ 8 <3 34 28 24 22 20 28 24 22 20 24 22 20 22 20 20>,
					/bits/ 8 <4 63 63 63 63 63 63 63 63 63 63 63 63 63 63 63>;
					paths-ru-bf =
					/bits/ 8 <6 27 15 8 3 0 21 14 9 5 17 12 9 15 11 13>,
					/bits/ 8 <1 32 20 13 8 4 26 19 14 10 22 17 14 20 16 18>,
					/bits/ 8 <2 33 21 14 9 5 27 20 15 11 23 18 15 21 17 19>,
					/bits/ 8 <3 34 22 15 10 6 28 21 16 12 24 19 16 22 18 20>,
					/bits/ 8 <4 63 63 63 63 63 63 63 63 63 63 63 63 63 63 63>;
				};
				r2 {
					channels = <100 100>;
					txs-delta = <0 0 0>;
					rates-cck = /bits/ 8 <63 63 63 63>;
					rates-ofdm = /bits/ 8 <37 37 37 37 37 37 37 37>;
					rates-mcs =
					/bits/ 8 <2 37 37 37 37 37 37 37 37 37 37>,
					/bits/ 8 <1 33 33 33 33 33 33 33 33 33 33>,
					/bits/ 8 <1 34 34 34 34 34 34 34 34 34 34>;
					rates-ru =
					/bits/ 8 <5 37 37 37 37 37 37 37 37 37 37 37 37>,
					/bits/ 8 <1 33 33 33 33 33 33 33 33 33 33 33 33>,
					/bits/ 8 <1 34 34 34 34 34 34 34 34 34 34 34 34>;
					rates-eht =
					/bits/ 8 <5 37 37 37 37 37 37 37 37 37 37 37 37 37 37 37 37>,
					/bits/ 8 <1 33 33 33 33 33 33 33 33 33 33 33 33 33 33 33 33>,
					/bits/ 8 <1 34 34 34 34 34 34 34 34 34 34 34 34 34 34 34 34>,
					/bits/ 8 <1 63 63 63 63 63 63 63 63 63 63 63 63 63 63 63 63>,
					/bits/ 8 <2 37 37 37 37 37 37 37 37 37 37 37 37 37 37 37 37>,
					/bits/ 8 <1 33 33 33 33 33 33 33 33 33 33 33 33 33 33 33 33>,
					/bits/ 8 <2 34 34 34 34 34 34 34 34 34 34 34 34 34 34 34 34>,
					/bits/ 8 <3 63 63 63 63 63 63 63 63 63 63 63 63 63 63 63 63>;
					paths-cck = /bits/ 8 <63 63 63 63 63>;
					paths-ofdm = /bits/ 8 <37 31 27 25 23>;
					paths-ofdm-bf = /bits/ 8 <25 18 13 9>;
					paths-ru =
					/bits/ 8 <7 37 31 27 25 23 31 27 25 23 27 25 23 25 23 23>,
					/bits/ 8 <2 33 27 23 21 19 27 23 21 19 23 21 19 21 19 19>,
					/bits/ 8 <3 34 28 24 22 20 28 24 22 20 24 22 20 22 20 20>,
					/bits/ 8 <4 63 63 63 63 63 63 63 63 63 63 63 63 63 63 63>;
					paths-ru-bf =
					/bits/ 8 <7 37 25 18 13 9 31 24 19 15 27 22 19 25 21 23>,
					/bits/ 8 <2 33 21 14 9 5 27 20 15 11 23 18 15 21 17 19>,
					/bits/ 8 <3 34 22 15 10 6 28 21 16 12 24 19 16 22 18 20>,
					/bits/ 8 <4 63 63 63 63 63 63 63 63 63 63 63 63 63 63 63>;
				};
				r3 {
					channels = <104 128>;
					txs-delta = <0 0 0>;
					rates-cck = /bits/ 8 <63 63 63 63>;
					rates-ofdm = /bits/ 8 <37 37 37 37 37 37 37 37>;
					rates-mcs =
					/bits/ 8 <3 37 37 37 37 37 37 37 37 37 37>,
					/bits/ 8 <1 34 34 34 34 34 34 34 34 34 34>;
					rates-ru =
					/bits/ 8 <6 37 37 37 37 37 37 37 37 37 37 37 37>,
					/bits/ 8 <1 34 34 34 34 34 34 34 34 34 34 34 34>;
					rates-eht =
					/bits/ 8 <6 37 37 37 37 37 37 37 37 37 37 37 37 37 37 37 37>,
					/bits/ 8 <1 34 34 34 34 34 34 34 34 34 34 34 34 34 34 34 34>,
					/bits/ 8 <1 63 63 63 63 63 63 63 63 63 63 63 63 63 63 63 63>,
					/bits/ 8 <3 37 37 37 37 37 37 37 37 37 37 37 37 37 37 37 37>,
					/bits/ 8 <2 34 34 34 34 34 34 34 34 34 34 34 34 34 34 34 34>,
					/bits/ 8 <3 63 63 63 63 63 63 63 63 63 63 63 63 63 63 63 63>;
					paths-cck = /bits/ 8 <63 63 63 63 63>;
					paths-ofdm = /bits/ 8 <37 31 27 25 23>;
					paths-ofdm-bf = /bits/ 8 <25 18 13 9>;
					paths-ru =
					/bits/ 8 <9 37 31 27 25 23 31 27 25 23 27 25 23 25 23 23>,
					/bits/ 8 <3 34 28 24 22 20 28 24 22 20 24 22 20 22 20 20>,
					/bits/ 8 <4 63 63 63 63 63 63 63 63 63 63 63 63 63 63 63>;
					paths-ru-bf =
					/bits/ 8 <9 37 25 18 13 9 31 24 19 15 27 22 19 25 21 23>,
					/bits/ 8 <3 34 22 15 10 6 28 21 16 12 24 19 16 22 18 20>,
					/bits/ 8 <4 63 63 63 63 63 63 63 63 63 63 63 63 63 63 63>;
				};
				r4 {
					channels = <132 132>;
					txs-delta = <0 0 0>;
					rates-cck = /bits/ 8 <63 63 63 63>;
					rates-ofdm = /bits/ 8 <37 37 37 37 37 37 37 37>;
					rates-mcs =
					/bits/ 8 <1 37 37 37 37 37 37 37 37 37 37>,
					/bits/ 8 <1 38 38 38 38 38 38 38 38 38 38>,
					/bits/ 8 <1 37 37 37 37 37 37 37 37 37 37>,
					/bits/ 8 <1 34 34 34 34 34 34 34 34 34 34>;
					rates-ru =
					/bits/ 8 <4 37 37 37 37 37 37 37 37 37 37 37 37>,
					/bits/ 8 <1 38 38 38 38 38 38 38 38 38 38 38 38>,
					/bits/ 8 <1 37 37 37 37 37 37 37 37 37 37 37 37>,
					/bits/ 8 <1 34 34 34 34 34 34 34 34 34 34 34 34>;
					rates-eht =
					/bits/ 8 <4 37 37 37 37 37 37 37 37 37 37 37 37 37 37 37 37>,
					/bits/ 8 <1 38 38 38 38 38 38 38 38 38 38 38 38 38 38 38 38>,
					/bits/ 8 <1 37 37 37 37 37 37 37 37 37 37 37 37 37 37 37 37>,
					/bits/ 8 <1 34 34 34 34 34 34 34 34 34 34 34 34 34 34 34 34>,
					/bits/ 8 <1 63 63 63 63 63 63 63 63 63 63 63 63 63 63 63 63>,
					/bits/ 8 <3 37 37 37 37 37 37 37 37 37 37 37 37 37 37 37 37>,
					/bits/ 8 <2 34 34 34 34 34 34 34 34 34 34 34 34 34 34 34 34>,
					/bits/ 8 <3 63 63 63 63 63 63 63 63 63 63 63 63 63 63 63 63>;
					paths-cck = /bits/ 8 <63 63 63 63 63>;
					paths-ofdm = /bits/ 8 <37 31 27 25 23>;
					paths-ofdm-bf = /bits/ 8 <25 18 13 9>;
					paths-ru =
					/bits/ 8 <6 37 31 27 25 23 31 27 25 23 27 25 23 25 23 23>,
					/bits/ 8 <1 38 32 28 26 24 32 28 26 24 28 26 24 26 24 24>,
					/bits/ 8 <2 37 31 27 25 23 31 27 25 23 27 25 23 25 23 23>,
					/bits/ 8 <3 34 28 24 22 20 28 24 22 20 24 22 20 22 20 20>,
					/bits/ 8 <4 63 63 63 63 63 63 63 63 63 63 63 63 63 63 63>;
					paths-ru-bf =
					/bits/ 8 <6 37 25 18 13 9 31 24 19 15 27 22 19 25 21 23>,
					/bits/ 8 <1 38 26 19 14 10 32 25 20 16 28 23 20 26 22 24>,
					/bits/ 8 <2 37 25 18 13 9 31 24 19 15 27 22 19 25 21 23>,
					/bits/ 8 <3 34 22 15 10 6 28 21 16 12 24 19 16 22 18 20>,
					/bits/ 8 <4 63 63 63 63 63 63 63 63 63 63 63 63 63 63 63>;
				};
				r5 {
					channels = <136 136>;
					txs-delta = <0 0 0>;
					rates-cck = /bits/ 8 <63 63 63 63>;
					rates-ofdm = /bits/ 8 <37 37 37 37 37 37 37 37>;
					rates-mcs =
					/bits/ 8 <1 37 37 37 37 37 37 37 37 37 37>,
					/bits/ 8 <2 38 38 38 38 38 38 38 38 38 38>,
					/bits/ 8 <1 34 34 34 34 34 34 34 34 34 34>;
					rates-ru =
					/bits/ 8 <4 37 37 37 37 37 37 37 37 37 37 37 37>,
					/bits/ 8 <2 38 38 38 38 38 38 38 38 38 38 38 38>,
					/bits/ 8 <1 34 34 34 34 34 34 34 34 34 34 34 34>;
					rates-eht =
					/bits/ 8 <4 37 37 37 37 37 37 37 37 37 37 37 37 37 37 37 37>,
					/bits/ 8 <2 38 38 38 38 38 38 38 38 38 38 38 38 38 38 38 38>,
					/bits/ 8 <1 34 34 34 34 34 34 34 34 34 34 34 34 34 34 34 34>,
					/bits/ 8 <1 63 63 63 63 63 63 63 63 63 63 63 63 63 63 63 63>,
					/bits/ 8 <2 37 37 37 37 37 37 37 37 37 37 37 37 37 37 37 37>,
					/bits/ 8 <1 38 38 38 38 38 38 38 38 38 38 38 38 38 38 38 38>,
					/bits/ 8 <2 34 34 34 34 34 34 34 34 34 34 34 34 34 34 34 34>,
					/bits/ 8 <3 63 63 63 63 63 63 63 63 63 63 63 63 63 63 63 63>;
					paths-cck = /bits/ 8 <63 63 63 63 63>;
					paths-ofdm = /bits/ 8 <37 31 27 25 23>;
					paths-ofdm-bf = /bits/ 8 <25 18 13 9>;
					paths-ru =
					/bits/ 8 <6 37 31 27 25 23 31 27 25 23 27 25 23 25 23 23>,
					/bits/ 8 <3 38 32 28 26 24 32 28 26 24 28 26 24 26 24 24>,
					/bits/ 8 <3 34 28 24 22 20 28 24 22 20 24 22 20 22 20 20>,
					/bits/ 8 <4 63 63 63 63 63 63 63 63 63 63 63 63 63 63 63>;
					paths-ru-bf =
					/bits/ 8 <6 37 25 18 13 9 31 24 19 15 27 22 19 25 21 23>,
					/bits/ 8 <3 38 26 19 14 10 32 25 20 16 28 23 20 26 22 24>,
					/bits/ 8 <3 34 22 15 10 6 28 21 16 12 24 19 16 22 18 20>,
					/bits/ 8 <4 63 63 63 63 63 63 63 63 63 63 63 63 63 63 63>;
				};
				r6 {
					channels = <140 140>;
					txs-delta = <0 0 0>;
					rates-cck = /bits/ 8 <63 63 63 63>;
					rates-ofdm = /bits/ 8 <38 38 38 38 38 38 38 38>;
					rates-mcs =
					/bits/ 8 <1 37 37 37 37 37 37 37 37 37 37>,
					/bits/ 8 <2 38 38 38 38 38 38 38 38 38 38>,
					/bits/ 8 <1 34 34 34 34 34 34 34 34 34 34>;
					rates-ru =
					/bits/ 8 <4 37 37 37 37 37 37 37 37 37 37 37 37>,
					/bits/ 8 <2 38 38 38 38 38 38 38 38 38 38 38 38>,
					/bits/ 8 <1 34 34 34 34 34 34 34 34 34 34 34 34>;
					rates-eht =
					/bits/ 8 <4 37 37 37 37 37 37 37 37 37 37 37 37 37 37 37 37>,
					/bits/ 8 <2 38 38 38 38 38 38 38 38 38 38 38 38 38 38 38 38>,
					/bits/ 8 <1 34 34 34 34 34 34 34 34 34 34 34 34 34 34 34 34>,
					/bits/ 8 <1 63 63 63 63 63 63 63 63 63 63 63 63 63 63 63 63>,
					/bits/ 8 <2 37 37 37 37 37 37 37 37 37 37 37 37 37 37 37 37>,
					/bits/ 8 <1 38 38 38 38 38 38 38 38 38 38 38 38 38 38 38 38>,
					/bits/ 8 <2 34 34 34 34 34 34 34 34 34 34 34 34 34 34 34 34>,
					/bits/ 8 <3 63 63 63 63 63 63 63 63 63 63 63 63 63 63 63 63>;
					paths-cck = /bits/ 8 <63 63 63 63 63>;
					paths-ofdm = /bits/ 8 <38 32 28 26 24>;
					paths-ofdm-bf = /bits/ 8 <26 19 14 10>;
					paths-ru =
					/bits/ 8 <6 37 31 27 25 23 31 27 25 23 27 25 23 25 23 23>,
					/bits/ 8 <3 38 32 28 26 24 32 28 26 24 28 26 24 26 24 24>,
					/bits/ 8 <3 34 28 24 22 20 28 24 22 20 24 22 20 22 20 20>,
					/bits/ 8 <4 63 63 63 63 63 63 63 63 63 63 63 63 63 63 63>;
					paths-ru-bf =
					/bits/ 8 <6 37 25 18 13 9 31 24 19 15 27 22 19 25 21 23>,
					/bits/ 8 <3 38 26 19 14 10 32 25 20 16 28 23 20 26 22 24>,
					/bits/ 8 <3 34 22 15 10 6 28 21 16 12 24 19 16 22 18 20>,
					/bits/ 8 <4 63 63 63 63 63 63 63 63 63 63 63 63 63 63 63>;
				};
				r7 {
					channels = <144 144>;
					txs-delta = <0 0 0>;
					rates-cck = /bits/ 8 <63 63 63 63>;
					rates-ofdm = /bits/ 8 <38 38 38 38 38 38 38 38>;
					rates-mcs =
					/bits/ 8 <3 38 38 38 38 38 38 38 38 38 38>,
					/bits/ 8 <1 34 34 34 34 34 34 34 34 34 34>;
					rates-ru =
					/bits/ 8 <6 38 38 38 38 38 38 38 38 38 38 38 38>,
					/bits/ 8 <1 34 34 34 34 34 34 34 34 34 34 34 34>;
					rates-eht =
					/bits/ 8 <6 38 38 38 38 38 38 38 38 38 38 38 38 38 38 38 38>,
					/bits/ 8 <1 34 34 34 34 34 34 34 34 34 34 34 34 34 34 34 34>,
					/bits/ 8 <1 63 63 63 63 63 63 63 63 63 63 63 63 63 63 63 63>,
					/bits/ 8 <3 38 38 38 38 38 38 38 38 38 38 38 38 38 38 38 38>,
					/bits/ 8 <2 34 34 34 34 34 34 34 34 34 34 34 34 34 34 34 34>,
					/bits/ 8 <3 63 63 63 63 63 63 63 63 63 63 63 63 63 63 63 63>;
					paths-cck = /bits/ 8 <63 63 63 63 63>;
					paths-ofdm = /bits/ 8 <38 32 28 26 24>;
					paths-ofdm-bf = /bits/ 8 <26 19 14 10>;
					paths-ru =
					/bits/ 8 <9 38 32 28 26 24 32 28 26 24 28 26 24 26 24 24>,
					/bits/ 8 <3 34 28 24 22 20 28 24 22 20 24 22 20 22 20 20>,
					/bits/ 8 <4 63 63 63 63 63 63 63 63 63 63 63 63 63 63 63>;
					paths-ru-bf =
					/bits/ 8 <9 38 26 19 14 10 32 25 20 16 28 23 20 26 22 24>,
					/bits/ 8 <3 34 22 15 10 6 28 21 16 12 24 19 16 22 18 20>,
					/bits/ 8 <4 63 63 63 63 63 63 63 63 63 63 63 63 63 63 63>;
				};
				r8 {
					channels = <149 149>;
					txs-delta = <0 0 0>;
					rates-cck = /bits/ 8 <63 63 63 63>;
					rates-ofdm = /bits/ 8 <57 57 57 57 57 57 57 57>;
					rates-mcs =
					/bits/ 8 <1 57 57 57 57 57 57 57 57 57 57>,
					/bits/ 8 <2 38 38 38 38 38 38 38 38 38 38>,
					/bits/ 8 <1 34 34 34 34 34 34 34 34 34 34>;
					rates-ru =
					/bits/ 8 <4 57 57 57 57 57 57 57 57 57 57 57 57>,
					/bits/ 8 <2 38 38 38 38 38 38 38 38 38 38 38 38>,
					/bits/ 8 <1 34 34 34 34 34 34 34 34 34 34 34 34>;
					rates-eht =
					/bits/ 8 <4 57 57 57 57 57 57 57 57 57 57 57 57 57 57 57 57>,
					/bits/ 8 <2 38 38 38 38 38 38 38 38 38 38 38 38 38 38 38 38>,
					/bits/ 8 <1 34 34 34 34 34 34 34 34 34 34 34 34 34 34 34 34>,
					/bits/ 8 <1 63 63 63 63 63 63 63 63 63 63 63 63 63 63 63 63>,
					/bits/ 8 <2 57 57 57 57 57 57 57 57 57 57 57 57 57 57 57 57>,
					/bits/ 8 <1 38 38 38 38 38 38 38 38 38 38 38 38 38 38 38 38>,
					/bits/ 8 <2 34 34 34 34 34 34 34 34 34 34 34 34 34 34 34 34>,
					/bits/ 8 <3 63 63 63 63 63 63 63 63 63 63 63 63 63 63 63 63>;
					paths-cck = /bits/ 8 <63 63 63 63 63>;
					paths-ofdm = /bits/ 8 <57 51 47 45 43>;
					paths-ofdm-bf = /bits/ 8 <45 38 33 29>;
					paths-ru =
					/bits/ 8 <6 57 51 47 45 43 51 47 45 43 47 45 43 45 43 43>,
					/bits/ 8 <3 38 32 28 26 24 32 28 26 24 28 26 24 26 24 24>,
					/bits/ 8 <3 34 28 24 22 20 28 24 22 20 24 22 20 22 20 20>,
					/bits/ 8 <4 63 63 63 63 63 63 63 63 63 63 63 63 63 63 63>;
					paths-ru-bf =
					/bits/ 8 <6 57 45 38 33 29 51 44 39 35 47 42 39 45 41 43>,
					/bits/ 8 <3 38 26 19 14 10 32 25 20 16 28 23 20 26 22 24>,
					/bits/ 8 <3 34 22 15 10 6 28 21 16 12 24 19 16 22 18 20>,
					/bits/ 8 <4 63 63 63 63 63 63 63 63 63 63 63 63 63 63 63>;
				};
				r9 {
					channels = <153 153>;
					txs-delta = <0 0 0>;
					rates-cck = /bits/ 8 <63 63 63 63>;
					rates-ofdm = /bits/ 8 <57 57 57 57 57 57 57 57>;
					rates-mcs =
					/bits/ 8 <1 57 57 57 57 57 57 57 57 57 57>,
					/bits/ 8 <1 55 55 55 55 55 55 55 55 55 55>,
					/bits/ 8 <1 38 38 38 38 38 38 38 38 38 38>,
					/bits/ 8 <1 34 34 34 34 34 34 34 34 34 34>;
					rates-ru =
					/bits/ 8 <4 57 57 57 57 57 57 57 57 57 57 57 57>,
					/bits/ 8 <1 55 55 55 55 55 55 55 55 55 55 55 55>,
					/bits/ 8 <1 38 38 38 38 38 38 38 38 38 38 38 38>,
					/bits/ 8 <1 34 34 34 34 34 34 34 34 34 34 34 34>;
					rates-eht =
					/bits/ 8 <4 57 57 57 57 57 57 57 57 57 57 57 57 57 57 57 57>,
					/bits/ 8 <1 55 55 55 55 55 55 55 55 55 55 55 55 55 55 55 55>,
					/bits/ 8 <1 38 38 38 38 38 38 38 38 38 38 38 38 38 38 38 38>,
					/bits/ 8 <1 34 34 34 34 34 34 34 34 34 34 34 34 34 34 34 34>,
					/bits/ 8 <1 63 63 63 63 63 63 63 63 63 63 63 63 63 63 63 63>,
					/bits/ 8 <2 57 57 57 57 57 57 57 57 57 57 57 57 57 57 57 57>,
					/bits/ 8 <1 38 38 38 38 38 38 38 38 38 38 38 38 38 38 38 38>,
					/bits/ 8 <2 34 34 34 34 34 34 34 34 34 34 34 34 34 34 34 34>,
					/bits/ 8 <3 63 63 63 63 63 63 63 63 63 63 63 63 63 63 63 63>;
					paths-cck = /bits/ 8 <63 63 63 63 63>;
					paths-ofdm = /bits/ 8 <57 51 47 45 43>;
					paths-ofdm-bf = /bits/ 8 <45 38 33 29>;
					paths-ru =
					/bits/ 8 <6 57 51 47 45 43 51 47 45 43 47 45 43 45 43 43>,
					/bits/ 8 <1 55 49 45 43 41 49 45 43 41 45 43 41 43 41 41>,
					/bits/ 8 <2 38 32 28 26 24 32 28 26 24 28 26 24 26 24 24>,
					/bits/ 8 <3 34 28 24 22 20 28 24 22 20 24 22 20 22 20 20>,
					/bits/ 8 <4 63 63 63 63 63 63 63 63 63 63 63 63 63 63 63>;
					paths-ru-bf =
					/bits/ 8 <6 57 45 38 33 29 51 44 39 35 47 42 39 45 41 43>,
					/bits/ 8 <1 55 43 36 31 27 49 42 37 33 45 40 37 43 39 41>,
					/bits/ 8 <2 38 26 19 14 10 32 25 20 16 28 23 20 26 22 24>,
					/bits/ 8 <3 34 22 15 10 6 28 21 16 12 24 19 16 22 18 20>,
					/bits/ 8 <4 63 63 63 63 63 63 63 63 63 63 63 63 63 63 63>;
				};
				r10 {
					channels = <157 181>;
					txs-delta = <0 0 0>;
					rates-cck = /bits/ 8 <63 63 63 63>;
					rates-ofdm = /bits/ 8 <57 57 57 57 57 57 57 57>;
					rates-mcs =
					/bits/ 8 <1 57 57 57 57 57 57 57 57 57 57>,
					/bits/ 8 <1 55 55 55 55 55 55 55 55 55 55>,
					/bits/ 8 <1 50 50 50 50 50 50 50 50 50 50>,
					/bits/ 8 <1 34 34 34 34 34 34 34 34 34 34>;
					rates-ru =
					/bits/ 8 <4 57 57 57 57 57 57 57 57 57 57 57 57>,
					/bits/ 8 <1 55 55 55 55 55 55 55 55 55 55 55 55>,
					/bits/ 8 <1 50 50 50 50 50 50 50 50 50 50 50 50>,
					/bits/ 8 <1 34 34 34 34 34 34 34 34 34 34 34 34>;
					rates-eht =
					/bits/ 8 <4 57 57 57 57 57 57 57 57 57 57 57 57 57 57 57 57>,
					/bits/ 8 <1 55 55 55 55 55 55 55 55 55 55 55 55 55 55 55 55>,
					/bits/ 8 <1 50 50 50 50 50 50 50 50 50 50 50 50 50 50 50 50>,
					/bits/ 8 <1 34 34 34 34 34 34 34 34 34 34 34 34 34 34 34 34>,
					/bits/ 8 <1 63 63 63 63 63 63 63 63 63 63 63 63 63 63 63 63>,
					/bits/ 8 <2 57 57 57 57 57 57 57 57 57 57 57 57 57 57 57 57>,
					/bits/ 8 <1 50 50 50 50 50 50 50 50 50 50 50 50 50 50 50 50>,
					/bits/ 8 <2 34 34 34 34 34 34 34 34 34 34 34 34 34 34 34 34>,
					/bits/ 8 <3 63 63 63 63 63 63 63 63 63 63 63 63 63 63 63 63>;
					paths-cck = /bits/ 8 <63 63 63 63 63>;
					paths-ofdm = /bits/ 8 <57 51 47 45 43>;
					paths-ofdm-bf = /bits/ 8 <45 38 33 29>;
					paths-ru =
					/bits/ 8 <6 57 51 47 45 43 51 47 45 43 47 45 43 45 43 43>,
					/bits/ 8 <1 55 49 45 43 41 49 45 43 41 45 43 41 43 41 41>,
					/bits/ 8 <2 50 44 40 38 36 44 40 38 36 40 38 36 38 36 36>,
					/bits/ 8 <3 34 28 24 22 20 28 24 22 20 24 22 20 22 20 20>,
					/bits/ 8 <4 63 63 63 63 63 63 63 63 63 63 63 63 63 63 63>;
					paths-ru-bf =
					/bits/ 8 <6 57 45 38 33 29 51 44 39 35 47 42 39 45 41 43>,
					/bits/ 8 <1 55 43 36 31 27 49 42 37 33 45 40 37 43 39 41>,
					/bits/ 8 <2 50 38 31 26 22 44 37 32 28 40 35 32 38 34 36>,
					/bits/ 8 <3 34 22 15 10 6 28 21 16 12 24 19 16 22 18 20>,
					/bits/ 8 <4 63 63 63 63 63 63 63 63 63 63 63 63 63 63 63>;
				};
			};
		};
	};
};
